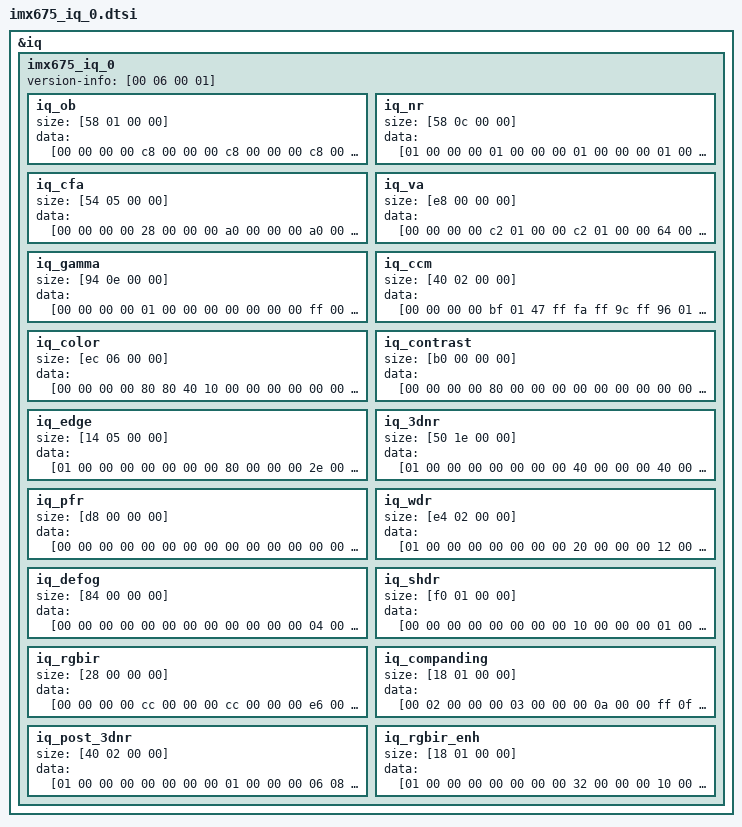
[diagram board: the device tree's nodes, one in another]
/*
 * Novatek Ltd. NA51055 BSP part of dts
 *
 * Cortex-A9
 *
 */

&iq {
	imx675_iq_0 {
		version-info = [00 06 00 01];
		iq_ob {
			size = [58 01 00 00];
			data = [00 00 00 00 c8 00 00 00 c8 00 00 00 c8 00 00 00 c8 00 00 00 c8 00 00 00 c8 00 00 00 c8 00 00 00 c8 00 00 00 c8 00 00 00 c8 00 00 00 c8 00 00 00 c8 00 00 00 c8 00 00 00 c8 00 00 00 c8 00 00 00 c8 00 00 00 c8 00 00 00 c8 00 00 00 c8 00 00 00 c8 00 00 00 c8 00 00 00 c8 00 00 00 c8 00 00 00 c8 00 00 00 c8 00 00 00 c8 00 00 00 c8 00 00 00 c8 00 00 00 c8 00 00 00 c8 00 00 00 c8 00 00 00 c8 00 00 00 c8 00 00 00 c8 00 00 00 c8 00 00 00 c8 00 00 00 c8 00 00 00 c8 00 00 00 c8 00 00 00 c8 00 00 00 c8 00 00 00 c8 00 00 00 c8 00 00 00 c8 00 00 00 c8 00 00 00 c8 00 00 00 c8 00 00 00 c8 00 00 00 c8 00 00 00 c8 00 00 00 c8 00 00 00 c8 00 00 00 c8 00 00 00 c8 00 00 00 c8 00 00 00 c8 00 00 00 c8 00 00 00 c8 00 00 00 c8 00 00 00 c8 00 00 00 c8 00 00 00 c8 00 00 00 c8 00 00 00 c8 00 00 00 c8 00 00 00 c8 00 00 00 c8 00 00 00 c8 00 00 00 c8 00 00 00 c8 00 00 00 c8 00 00 00 c8 00 00 00 c8 00 00 00 c8 00 00 00 c8 00 00 00 c8 00 00 00 c8 00 00 00 c8 00 00 00 c8 00 00 00 c8 00 00 00 c8 00 00 00 c8 00 00 00 c8 00 00 00 c8 00 00 00 c8 00 00 00];
		};
		iq_nr {
			size = [58 0c 00 00];
			data = [01 00 00 00 01 00 00 00 01 00 00 00 01 00 00 00 01 00 00 00 00 00 00 00 00 00 00 00 00 01 00 00 00 00 00 00 ff 0f 00 00 ff 0f 00 00 ff 0f 00 00 ff 0f 00 00 ff 0f 00 00 ff 0f 00 00 ff 0f 00 00 ff 0f 00 00 ff 0f 00 00 ff 0f 00 00 00 01 80 00 00 00 00 00 00 00 00 00 00 00 00 00 00 00 00 00 00 00 00 00 00 00 00 00 00 00 00 00 00 00 00 00 00 00 00 00 00 00 00 00 00 00 00 00 00 00 00 00 00 00 00 00 00 00 00 00 00 00 00 00 00 00 00 00 00 00 00 00 00 00 00 00 00 00 00 00 00 00 00 00 00 00 00 00 00 00 00 00 00 00 00 00 00 00 00 00 00 00 00 00 80 00 00 00 00 00 00 00 00 00 00 00 00 00 00 00 00 00 00 00 00 00 00 00 00 00 00 00 02 00 00 00 02 00 00 00 00 00 00 00 c6 02 00 00 0c 04 00 00 af 06 00 00 3d 09 00 00 41 0f 00 00 c6 02 00 00 0c 04 00 00 af 06 00 00 3d 09 00 00 41 0f 00 00 00 00 80 00 00 00 00 00 01 00 00 00 02 00 00 00 02 00 00 00 02 00 00 00 03 00 00 00 00 00 00 00 02 00 00 00 02 00 00 00 03 00 00 00 03 00 00 00 03 00 00 00 03 00 00 00 04 00 00 00 04 00 00 00 04 00 00 00 04 00 00 00 04 00 00 00 05 00 00 00 05 00 00 00 05 00 00 00 05 00 00 00 05 00 00 00 00 00 00 00 02 00 00 00 80 00 00 00 08 00 00 00 08 00 00 00 08 00 00 00 08 00 00 00 00 00 00 00 01 00 00 00 00 00 00 00 00 00 00 00 00 00 00 00 c6 02 00 00 0c 04 00 00 af 06 00 00 3d 09 00 00 41 0f 00 00 c6 02 00 00 0c 04 00 00 af 06 00 00 3d 09 00 00 41 0f 00 00 02 00 80 00 00 00 00 00 01 00 00 00 02 00 00 00 02 00 00 00 03 00 00 00 03 00 00 00 02 00 00 00 03 00 00 00 05 00 00 00 07 00 00 00 08 00 00 00 08 00 00 00 08 00 00 00 09 00 00 00 0a 00 00 00 0a 00 00 00 0b 00 00 00 0b 00 00 00 0c 00 00 00 0c 00 00 00 0d 00 00 00 0d 00 00 00 0e 00 00 00 00 00 00 00 03 00 00 00 80 00 00 00 08 00 00 00 08 00 00 00 08 00 00 00 08 00 00 00 00 00 00 00 04 00 00 00 00 00 00 00 00 00 00 00 00 00 00 00 20 00 00 00 00 02 00 00 c0 03 00 00 a0 05 00 00 00 0a 00 00 c6 02 00 00 0c 04 00 00 af 06 00 00 3d 09 00 00 41 0f 00 00 02 00 80 00 01 00 00 00 02 00 00 00 02 00 00 00 03 00 00 00 04 00 00 00 05 00 00 00 03 00 00 00 05 00 00 00 08 00 00 00 09 00 00 00 0a 00 00 00 0a 00 00 00 0a 00 00 00 0d 00 00 00 0e 00 00 00 0f 00 00 00 10 00 00 00 0f 00 00 00 0f 00 00 00 10 00 00 00 10 00 00 00 11 00 00 00 12 00 00 00 00 00 00 00 04 00 00 00 80 00 00 00 08 00 00 00 08 00 00 00 08 00 00 00 08 00 00 00 00 00 00 00 04 00 00 00 01 00 00 00 01 00 00 00 00 00 00 00 20 00 00 00 a0 00 00 00 80 01 00 00 00 02 00 00 00 03 00 00 c6 02 00 00 0c 04 00 00 af 06 00 00 3d 09 00 00 41 0f 00 00 09 00 80 00 03 00 00 00 04 00 00 00 04 00 00 00 05 00 00 00 05 00 00 00 06 00 00 00 04 00 00 00 06 00 00 00 09 00 00 00 0b 00 00 00 0b 00 00 00 0c 00 00 00 0e 00 00 00 0f 00 00 00 10 00 00 00 12 00 00 00 12 00 00 00 13 00 00 00 14 00 00 00 14 00 00 00 14 00 00 00 14 00 00 00 14 00 00 00 00 00 00 00 05 00 00 00 80 00 00 00 08 00 00 00 08 00 00 00 08 00 00 00 08 00 00 00 00 00 00 00 06 00 00 00 01 00 00 00 01 00 00 00 00 00 00 00 20 00 00 00 a0 00 00 00 80 01 00 00 00 02 00 00 00 03 00 00 c6 02 00 00 0c 04 00 00 af 06 00 00 3d 09 00 00 41 0f 00 00 09 00 80 00 04 00 00 00 04 00 00 00 05 00 00 00 06 00 00 00 07 00 00 00 07 00 00 00 06 00 00 00 0a 00 00 00 0e 00 00 00 10 00 00 00 11 00 00 00 13 00 00 00 15 00 00 00 17 00 00 00 18 00 00 00 1a 00 00 00 1b 00 00 00 1b 00 00 00 1b 00 00 00 1b 00 00 00 1b 00 00 00 1b 00 00 00 1b 00 00 00 00 00 00 00 05 00 00 00 80 00 00 00 08 00 00 00 08 00 00 00 08 00 00 00 08 00 00 00 01 00 00 00 08 00 00 00 02 00 00 00 02 00 00 00 00 00 00 00 20 00 00 00 64 00 00 00 c8 00 00 00 2c 01 00 00 00 02 00 00 c6 02 00 00 0c 04 00 00 af 06 00 00 3d 09 00 00 41 0f 00 00 09 00 80 00 06 00 00 00 07 00 00 00 08 00 00 00 09 00 00 00 09 00 00 00 0b 00 00 00 0c 00 00 00 0f 00 00 00 14 00 00 00 16 00 00 00 17 00 00 00 19 00 00 00 1b 00 00 00 1d 00 00 00 1f 00 00 00 21 00 00 00 22 00 00 00 24 00 00 00 25 00 00 00 27 00 00 00 28 00 00 00 29 00 00 00 2b 00 00 00 00 00 00 00 06 00 00 00 80 00 00 00 0a 00 00 00 0a 00 00 00 10 00 00 00 10 00 00 00 01 00 00 00 0a 00 00 00 02 00 00 00 02 00 00 00 00 00 00 00 20 00 00 00 90 00 00 00 c0 00 00 00 80 01 00 00 80 02 00 00 c6 02 00 00 0c 04 00 00 af 06 00 00 3d 09 00 00 41 0f 00 00 09 00 80 00 00 00 00 00 06 00 00 00 09 00 00 00 0b 00 00 00 0c 00 00 00 12 00 00 00 00 00 00 00 0c 00 00 00 0f 00 00 00 1c 00 00 00 1f 00 00 00 21 00 00 00 24 00 00 00 26 00 00 00 28 00 00 00 2a 00 00 00 2c 00 00 00 2e 00 00 00 30 00 00 00 31 00 00 00 33 00 00 00 34 00 00 00 36 00 00 00 02 00 00 00 08 00 00 00 40 00 00 00 0a 00 00 00 0a 00 00 00 10 00 00 00 10 00 00 00 00 00 00 00 0a 00 00 00 02 00 00 00 02 00 00 00 00 00 00 00 20 00 00 00 80 00 00 00 a0 00 00 00 00 01 00 00 00 02 00 00 c6 02 00 00 0c 04 00 00 af 06 00 00 3d 09 00 00 41 0f 00 00 09 00 80 00 00 00 00 00 06 00 00 00 08 00 00 00 0a 00 00 00 0c 00 00 00 11 00 00 00 00 00 00 00 10 00 00 00 17 00 00 00 1c 00 00 00 20 00 00 00 24 00 00 00 28 00 00 00 2b 00 00 00 2e 00 00 00 31 00 00 00 33 00 00 00 36 00 00 00 38 00 00 00 3b 00 00 00 3d 00 00 00 3f 00 00 00 41 00 00 00 00 00 00 00 20 00 00 00 40 00 00 00 10 00 00 00 10 00 00 00 10 00 00 00 10 00 00 00 00 00 00 00 10 00 00 00 02 00 00 00 02 00 00 00 00 00 00 00 c6 02 00 00 0c 04 00 00 af 06 00 00 3d 09 00 00 41 0f 00 00 c6 02 00 00 0c 04 00 00 af 06 00 00 3d 09 00 00 41 0f 00 00 09 00 80 00 00 00 00 00 0b 00 00 00 10 00 00 00 13 00 00 00 16 00 00 00 20 00 00 00 00 00 00 00 0f 00 00 00 1e 00 00 00 25 00 00 00 2b 00 00 00 30 00 00 00 34 00 00 00 39 00 00 00 3d 00 00 00 40 00 00 00 44 00 00 00 47 00 00 00 4a 00 00 00 4d 00 00 00 50 00 00 00 53 00 00 00 56 00 00 00 00 00 00 00 20 00 00 00 40 00 00 00 10 00 00 00 10 00 00 00 10 00 00 00 10 00 00 00 00 00 00 00 12 00 00 00 02 00 00 00 03 00 00 00 00 00 00 00 c6 02 00 00 0c 04 00 00 af 06 00 00 3d 09 00 00 41 0f 00 00 c6 02 00 00 0c 04 00 00 af 06 00 00 3d 09 00 00 41 0f 00 00 09 00 80 00 00 00 00 00 11 00 00 00 19 00 00 00 1f 00 00 00 23 00 00 00 32 00 00 00 00 00 00 00 18 00 00 00 2e 00 00 00 3f 00 00 00 49 00 00 00 52 00 00 00 5a 00 00 00 61 00 00 00 68 00 00 00 6e 00 00 00 74 00 00 00 7a 00 00 00 7f 00 00 00 84 00 00 00 89 00 00 00 8e 00 00 00 93 00 00 00 00 00 00 00 20 00 00 00 40 00 00 00 10 00 00 00 10 00 00 00 10 00 00 00 10 00 00 00 00 00 00 00 16 00 00 00 02 00 00 00 03 00 00 00 00 00 00 00 c6 02 00 00 0c 04 00 00 af 06 00 00 3d 09 00 00 41 0f 00 00 c6 02 00 00 0c 04 00 00 af 06 00 00 3d 09 00 00 41 0f 00 00 09 00 80 00 00 00 00 00 21 00 00 00 2f 00 00 00 3a 00 00 00 43 00 00 00 5e 00 00 00 00 00 00 00 38 00 00 00 4f 00 00 00 60 00 00 00 70 00 00 00 7d 00 00 00 89 00 00 00 94 00 00 00 9e 00 00 00 a8 00 00 00 b1 00 00 00 b9 00 00 00 c1 00 00 00 c9 00 00 00 d1 00 00 00 d8 00 00 00 e0 00 00 00 00 00 00 00 20 00 00 00 40 00 00 00 10 00 00 00 10 00 00 00 10 00 00 00 10 00 00 00 00 00 00 00 16 00 00 00 02 00 00 00 03 00 00 00 00 00 00 00 c6 02 00 00 0c 04 00 00 af 06 00 00 3d 09 00 00 41 0f 00 00 c6 02 00 00 0c 04 00 00 af 06 00 00 3d 09 00 00 41 0f 00 00 09 00 80 00 00 00 00 00 10 00 00 00 16 00 00 00 1c 00 00 00 20 00 00 00 2d 00 00 00 00 00 00 00 12 00 00 00 18 00 00 00 20 00 00 00 25 00 00 00 2a 00 00 00 2e 00 00 00 31 00 00 00 35 00 00 00 38 00 00 00 3b 00 00 00 3e 00 00 00 41 00 00 00 43 00 00 00 46 00 00 00 48 00 00 00 4b 00 00 00 00 00 00 00 20 00 00 00 20 00 00 00 10 00 00 00 10 00 00 00 10 00 00 00 10 00 00 00 00 00 00 00 18 00 00 00 02 00 00 00 03 00 00 00 00 00 00 00 14 02 00 00 03 03 00 00 f8 04 00 00 34 07 00 00 e3 0b 00 00 14 02 00 00 03 03 00 00 f8 04 00 00 34 07 00 00 e3 0b 00 00 09 00 80 00 00 00 00 00 11 00 00 00 18 00 00 00 1e 00 00 00 23 00 00 00 31 00 00 00 00 00 00 00 30 00 00 00 43 00 00 00 53 00 00 00 60 00 00 00 6b 00 00 00 75 00 00 00 7e 00 00 00 87 00 00 00 90 00 00 00 97 00 00 00 9f 00 00 00 a6 00 00 00 ad 00 00 00 b3 00 00 00 b9 00 00 00 c0 00 00 00 00 00 00 00 20 00 00 00 20 00 00 00 18 00 00 00 18 00 00 00 18 00 00 00 18 00 00 00 00 00 00 00 12 00 00 00 02 00 00 00 02 00 00 00 00 00 00 00 9a 01 00 00 53 02 00 00 d6 03 00 00 90 05 00 00 2e 09 00 00 9a 01 00 00 53 02 00 00 d6 03 00 00 90 05 00 00 2e 09 00 00 09 00 80 00 00 00 00 00 11 00 00 00 18 00 00 00 1e 00 00 00 23 00 00 00 31 00 00 00 00 00 00 00 30 00 00 00 43 00 00 00 53 00 00 00 60 00 00 00 6b 00 00 00 75 00 00 00 7e 00 00 00 87 00 00 00 90 00 00 00 97 00 00 00 9f 00 00 00 a6 00 00 00 ad 00 00 00 b3 00 00 00 b9 00 00 00 c0 00 00 00 00 00 00 00 20 00 00 00 20 00 00 00 18 00 00 00 18 00 00 00 18 00 00 00 18 00 00 00 00 00 00 00 12 00 00 00 02 00 00 00 02 00 00 00 00 00 00 00 9a 01 00 00 53 02 00 00 d6 03 00 00 90 05 00 00 2e 09 00 00 9a 01 00 00 53 02 00 00 d6 03 00 00 90 05 00 00 2e 09 00 00 09 00 80 00 00 00 00 00 11 00 00 00 18 00 00 00 1e 00 00 00 23 00 00 00 31 00 00 00 00 00 00 00 30 00 00 00 43 00 00 00 53 00 00 00 60 00 00 00 6b 00 00 00 75 00 00 00 7e 00 00 00 87 00 00 00 90 00 00 00 97 00 00 00 9f 00 00 00 a6 00 00 00 ad 00 00 00 b3 00 00 00 b9 00 00 00 c0 00 00 00 00 00 00 00 20 00 00 00 20 00 00 00 18 00 00 00 18 00 00 00 18 00 00 00 18 00 00 00 00 00 00 00 12 00 00 00 02 00 00 00 02 00 00 00 00 00 00 00 9a 01 00 00 53 02 00 00 d6 03 00 00 90 05 00 00 2e 09 00 00 9a 01 00 00 53 02 00 00 d6 03 00 00 90 05 00 00 2e 09 00 00 09 00 80 00 00 00 00 00 11 00 00 00 18 00 00 00 1e 00 00 00 23 00 00 00 31 00 00 00 00 00 00 00 30 00 00 00 43 00 00 00 53 00 00 00 60 00 00 00 6b 00 00 00 75 00 00 00 7e 00 00 00 87 00 00 00 90 00 00 00 97 00 00 00 9f 00 00 00 a6 00 00 00 ad 00 00 00 b3 00 00 00 b9 00 00 00 c0 00 00 00 00 00 00 00 20 00 00 00 20 00 00 00 18 00 00 00 18 00 00 00 18 00 00 00 18 00 00 00 00 00 00 00 12 00 00 00 02 00 00 00 02 00 00 00];
		};
		iq_cfa {
			size = [54 05 00 00];
			data = [00 00 00 00 28 00 00 00 a0 00 00 00 a0 00 00 00 40 00 00 00 0f 00 00 00 0f 00 00 00 07 00 00 00 04 00 00 00 03 00 00 00 02 00 00 00 02 00 00 00 01 00 00 00 01 00 00 00 01 00 00 00 01 00 00 00 00 00 00 00 00 00 00 00 00 00 00 00 00 00 00 00 00 00 00 00 28 00 00 00 a0 00 00 00 a0 00 00 00 40 00 00 00 0f 00 00 00 0f 00 00 00 07 00 00 00 04 00 00 00 03 00 00 00 02 00 00 00 02 00 00 00 01 00 00 00 01 00 00 00 01 00 00 00 01 00 00 00 00 00 00 00 00 00 00 00 00 00 00 00 00 00 00 00 00 00 00 00 28 00 00 00 a0 00 00 00 a0 00 00 00 40 00 00 00 0f 00 00 00 0f 00 00 00 07 00 00 00 04 00 00 00 03 00 00 00 02 00 00 00 02 00 00 00 01 00 00 00 01 00 00 00 01 00 00 00 01 00 00 00 00 00 00 00 00 00 00 00 00 00 00 00 00 00 00 00 00 00 00 00 28 00 00 00 a0 00 00 00 a0 00 00 00 40 00 00 00 0f 00 00 00 0f 00 00 00 07 00 00 00 04 00 00 00 03 00 00 00 02 00 00 00 02 00 00 00 01 00 00 00 01 00 00 00 01 00 00 00 01 00 00 00 00 00 00 00 00 00 00 00 00 00 00 00 00 00 00 00 00 00 00 00 28 00 00 00 a0 00 00 00 a0 00 00 00 40 00 00 00 0f 00 00 00 0f 00 00 00 07 00 00 00 04 00 00 00 03 00 00 00 02 00 00 00 02 00 00 00 01 00 00 00 01 00 00 00 01 00 00 00 01 00 00 00 00 00 00 00 00 00 00 00 00 00 00 00 00 00 00 00 00 00 00 00 28 00 00 00 a0 00 00 00 a0 00 00 00 40 00 00 00 0f 00 00 00 0f 00 00 00 07 00 00 00 04 00 00 00 03 00 00 00 02 00 00 00 02 00 00 00 01 00 00 00 01 00 00 00 01 00 00 00 01 00 00 00 00 00 00 00 00 00 00 00 00 00 00 00 00 00 00 00 00 00 00 00 28 00 00 00 a0 00 00 00 a0 00 00 00 40 00 00 00 0f 00 00 00 0f 00 00 00 07 00 00 00 04 00 00 00 03 00 00 00 02 00 00 00 02 00 00 00 01 00 00 00 01 00 00 00 01 00 00 00 01 00 00 00 00 00 00 00 00 00 00 00 00 00 00 00 00 00 00 00 00 00 00 00 28 00 00 00 a0 00 00 00 a0 00 00 00 40 00 00 00 0f 00 00 00 0f 00 00 00 07 00 00 00 04 00 00 00 03 00 00 00 02 00 00 00 02 00 00 00 01 00 00 00 01 00 00 00 01 00 00 00 01 00 00 00 00 00 00 00 00 00 00 00 00 00 00 00 00 00 00 00 00 00 00 00 28 00 00 00 a0 00 00 00 a0 00 00 00 40 00 00 00 0f 00 00 00 0f 00 00 00 07 00 00 00 04 00 00 00 03 00 00 00 02 00 00 00 02 00 00 00 01 00 00 00 01 00 00 00 01 00 00 00 01 00 00 00 00 00 00 00 00 00 00 00 00 00 00 00 00 00 00 00 00 00 00 00 28 00 00 00 a0 00 00 00 a0 00 00 00 40 00 00 00 0f 00 00 00 0f 00 00 00 07 00 00 00 04 00 00 00 03 00 00 00 02 00 00 00 02 00 00 00 01 00 00 00 01 00 00 00 01 00 00 00 01 00 00 00 00 00 00 00 00 00 00 00 00 00 00 00 00 00 00 00 00 00 00 00 28 00 00 00 a0 00 00 00 a0 00 00 00 40 00 00 00 0f 00 00 00 0f 00 00 00 07 00 00 00 04 00 00 00 03 00 00 00 02 00 00 00 02 00 00 00 01 00 00 00 01 00 00 00 01 00 00 00 01 00 00 00 00 00 00 00 00 00 00 00 00 00 00 00 00 00 00 00 00 00 00 00 28 00 00 00 a0 00 00 00 a0 00 00 00 40 00 00 00 0f 00 00 00 0f 00 00 00 07 00 00 00 04 00 00 00 03 00 00 00 02 00 00 00 02 00 00 00 01 00 00 00 01 00 00 00 01 00 00 00 01 00 00 00 00 00 00 00 00 00 00 00 00 00 00 00 00 00 00 00 00 00 00 00 28 00 00 00 a0 00 00 00 a0 00 00 00 40 00 00 00 0f 00 00 00 0f 00 00 00 07 00 00 00 04 00 00 00 03 00 00 00 02 00 00 00 02 00 00 00 01 00 00 00 01 00 00 00 01 00 00 00 01 00 00 00 00 00 00 00 00 00 00 00 00 00 00 00 00 00 00 00 00 00 00 00 28 00 00 00 a0 00 00 00 a0 00 00 00 40 00 00 00 0f 00 00 00 0f 00 00 00 07 00 00 00 04 00 00 00 03 00 00 00 02 00 00 00 02 00 00 00 01 00 00 00 01 00 00 00 01 00 00 00 01 00 00 00 00 00 00 00 00 00 00 00 00 00 00 00 00 00 00 00 00 00 00 00 28 00 00 00 a0 00 00 00 a0 00 00 00 40 00 00 00 0f 00 00 00 0f 00 00 00 07 00 00 00 04 00 00 00 03 00 00 00 02 00 00 00 02 00 00 00 01 00 00 00 01 00 00 00 01 00 00 00 01 00 00 00 00 00 00 00 00 00 00 00 00 00 00 00 00 00 00 00 00 00 00 00 28 00 00 00 a0 00 00 00 a0 00 00 00 40 00 00 00 0f 00 00 00 0f 00 00 00 07 00 00 00 04 00 00 00 03 00 00 00 02 00 00 00 02 00 00 00 01 00 00 00 01 00 00 00 01 00 00 00 01 00 00 00 00 00 00 00 00 00 00 00 00 00 00 00 00 00 00 00 00 00 00 00 28 00 00 00 a0 00 00 00 a0 00 00 00 40 00 00 00 0f 00 00 00 0f 00 00 00 07 00 00 00 04 00 00 00 03 00 00 00 02 00 00 00 02 00 00 00 01 00 00 00 01 00 00 00 01 00 00 00 01 00 00 00 00 00 00 00 00 00 00 00 00 00 00 00 00 00 00 00 00 00 00 00];
		};
		iq_va {
			size = [e8 00 00 00];
			data = [00 00 00 00 c2 01 00 00 c2 01 00 00 64 00 00 00 64 00 00 00 c8 00 00 00 c8 00 00 00 64 00 00 00 64 00 00 00 bc 02 00 00 c8 00 00 00 64 00 00 00 64 00 00 00 c8 00 00 00 bc 02 00 00 64 00 00 00 64 00 00 00 bc 02 00 00 bc 02 00 00 64 00 00 00 64 00 00 00 02 ff 00 00 03 02 00 ff 00 03 06 00 08 00 06 00 08 00 06 00 08 00 06 00 08 00 06 00 08 00 06 00 08 00 06 00 08 00 06 00 08 00 06 00 08 00 06 00 08 00 06 00 08 00 06 00 08 00 06 00 08 00 06 00 08 00 06 00 08 00 06 00 08 00 06 00 08 00 06 00 08 00 06 00 08 00 06 00 08 00 06 00 08 00 06 00 08 00 06 00 08 00 06 00 08 00 06 00 08 00 06 00 08 00 06 00 08 00 06 00 08 00 06 00 08 00 06 00 08 00 06 00 08 00 06 00 08 00 06 00 08 00 06 00 08 00 00 00];
		};
		iq_gamma {
			size = [94 0e 00 00];
			data = [00 00 00 00 01 00 00 00 00 00 00 00 ff 00 00 00 ff 00 00 00 ff 00 00 00 ff 00 00 00 ff 00 00 00 ff 00 00 00 ff 00 00 00 ff 00 00 00 ff 00 00 00 ff 00 00 00 ff 00 00 00 ff 00 00 00 ff 00 00 00 ff 00 00 00 ff 00 00 00 ff 00 00 00 ff 00 00 00 00 00 00 00 08 00 00 00 10 00 00 00 18 00 00 00 1c 00 00 00 20 00 00 00 24 00 00 00 26 00 00 00 28 00 00 00 29 00 00 00 2a 00 00 00 2b 00 00 00 2c 00 00 00 2d 00 00 00 2e 00 00 00 2f 00 00 00 30 00 00 00 31 00 00 00 32 00 00 00 33 00 00 00 34 00 00 00 35 00 00 00 36 00 00 00 37 00 00 00 38 00 00 00 39 00 00 00 3a 00 00 00 3b 00 00 00 3c 00 00 00 3d 00 00 00 3e 00 00 00 3f 00 00 00 03 00 00 00 03 00 00 00 03 00 00 00 02 00 00 00 02 00 00 00 02 00 00 00 01 00 00 00 01 00 00 00 00 00 00 00 00 00 00 00 00 00 00 00 00 00 00 00 00 00 00 00 00 00 00 00 00 00 00 00 00 00 00 00 00 00 00 00 00 00 00 00 00 00 00 00 00 00 00 00 00 00 00 00 00 00 00 00 00 00 00 00 00 00 00 00 00 00 00 00 00 00 00 00 00 00 00 00 00 00 00 00 00 00 00 00 00 00 00 00 00 00 00 00 00 00 00 00 00 00 00 00 1a 00 00 00 32 00 00 00 46 00 00 00 5a 00 00 00 6e 00 00 00 82 00 00 00 92 00 00 00 a4 00 00 00 b6 00 00 00 c9 00 00 00 dc 00 00 00 f0 00 00 00 03 01 00 00 17 01 00 00 2c 01 00 00 40 01 00 00 52 01 00 00 65 01 00 00 77 01 00 00 89 01 00 00 9a 01 00 00 ab 01 00 00 bb 01 00 00 cc 01 00 00 ef 01 00 00 12 02 00 00 35 02 00 00 59 02 00 00 76 02 00 00 94 02 00 00 b1 02 00 00 ce 02 00 00 ea 02 00 00 06 03 00 00 21 03 00 00 3d 03 00 00 75 03 00 00 af 03 00 00 e9 03 00 00 24 04 00 00 9b 04 00 00 14 05 00 00 90 05 00 00 09 06 00 00 86 06 00 00 00 07 00 00 80 07 00 00 00 08 00 00 80 08 00 00 00 09 00 00 80 09 00 00 00 0a 00 00 80 0a 00 00 00 0b 00 00 80 0b 00 00 00 0c 00 00 80 0c 00 00 00 0d 00 00 80 0d 00 00 00 0e 00 00 80 0e 00 00 00 0f 00 00 80 0f 00 00 ff 0f 00 00 00 00 00 00 08 00 00 00 10 00 00 00 18 00 00 00 1c 00 00 00 20 00 00 00 24 00 00 00 26 00 00 00 28 00 00 00 29 00 00 00 2a 00 00 00 2b 00 00 00 2c 00 00 00 2d 00 00 00 2e 00 00 00 2f 00 00 00 30 00 00 00 31 00 00 00 32 00 00 00 33 00 00 00 34 00 00 00 35 00 00 00 36 00 00 00 37 00 00 00 38 00 00 00 39 00 00 00 3a 00 00 00 3b 00 00 00 3c 00 00 00 3d 00 00 00 3e 00 00 00 3f 00 00 00 03 00 00 00 03 00 00 00 03 00 00 00 02 00 00 00 02 00 00 00 02 00 00 00 01 00 00 00 01 00 00 00 00 00 00 00 00 00 00 00 00 00 00 00 00 00 00 00 00 00 00 00 00 00 00 00 00 00 00 00 00 00 00 00 00 00 00 00 00 00 00 00 00 00 00 00 00 00 00 00 00 00 00 00 00 00 00 00 00 00 00 00 00 00 00 00 00 00 00 00 00 00 00 00 00 00 00 00 00 00 00 00 00 00 00 00 00 00 00 00 00 00 00 00 00 00 00 00 05 00 00 00 00 00 00 00 00 00 00 00 10 00 00 00 20 00 00 00 30 00 00 00 40 00 00 00 50 00 00 00 60 00 00 00 70 00 00 00 80 00 00 00 90 00 00 00 a0 00 00 00 b0 00 00 00 c0 00 00 00 d0 00 00 00 e0 00 00 00 f0 00 00 00 00 01 00 00 10 01 00 00 20 01 00 00 30 01 00 00 40 01 00 00 50 01 00 00 60 01 00 00 70 01 00 00 80 01 00 00 a0 01 00 00 c0 01 00 00 e0 01 00 00 00 02 00 00 20 02 00 00 40 02 00 00 60 02 00 00 80 02 00 00 a0 02 00 00 c0 02 00 00 e0 02 00 00 00 03 00 00 40 03 00 00 80 03 00 00 c0 03 00 00 00 04 00 00 80 04 00 00 00 05 00 00 80 05 00 00 00 06 00 00 80 06 00 00 00 07 00 00 80 07 00 00 00 08 00 00 80 08 00 00 00 09 00 00 80 09 00 00 00 0a 00 00 80 0a 00 00 00 0b 00 00 80 0b 00 00 00 0c 00 00 80 0c 00 00 00 0d 00 00 80 0d 00 00 00 0e 00 00 80 0e 00 00 00 0f 00 00 80 0f 00 00 ff 0f 00 00 19 00 00 00 00 00 00 00 10 00 00 00 20 00 00 00 30 00 00 00 40 00 00 00 50 00 00 00 60 00 00 00 70 00 00 00 80 00 00 00 90 00 00 00 a0 00 00 00 b0 00 00 00 c0 00 00 00 d0 00 00 00 e0 00 00 00 f0 00 00 00 00 01 00 00 10 01 00 00 20 01 00 00 30 01 00 00 40 01 00 00 50 01 00 00 60 01 00 00 70 01 00 00 80 01 00 00 a0 01 00 00 c0 01 00 00 e0 01 00 00 00 02 00 00 20 02 00 00 40 02 00 00 60 02 00 00 80 02 00 00 a0 02 00 00 c0 02 00 00 e0 02 00 00 00 03 00 00 40 03 00 00 80 03 00 00 c0 03 00 00 00 04 00 00 80 04 00 00 00 05 00 00 80 05 00 00 00 06 00 00 80 06 00 00 00 07 00 00 80 07 00 00 00 08 00 00 80 08 00 00 00 09 00 00 80 09 00 00 00 0a 00 00 80 0a 00 00 00 0b 00 00 80 0b 00 00 00 0c 00 00 80 0c 00 00 00 0d 00 00 80 0d 00 00 00 0e 00 00 80 0e 00 00 00 0f 00 00 80 0f 00 00 ff 0f 00 00 32 00 00 00 00 00 00 00 10 00 00 00 20 00 00 00 30 00 00 00 40 00 00 00 50 00 00 00 60 00 00 00 70 00 00 00 80 00 00 00 90 00 00 00 a0 00 00 00 b0 00 00 00 c0 00 00 00 d0 00 00 00 e0 00 00 00 f0 00 00 00 00 01 00 00 10 01 00 00 20 01 00 00 30 01 00 00 40 01 00 00 50 01 00 00 60 01 00 00 70 01 00 00 80 01 00 00 a0 01 00 00 c0 01 00 00 e0 01 00 00 00 02 00 00 20 02 00 00 40 02 00 00 60 02 00 00 80 02 00 00 a0 02 00 00 c0 02 00 00 e0 02 00 00 00 03 00 00 40 03 00 00 80 03 00 00 c0 03 00 00 00 04 00 00 80 04 00 00 00 05 00 00 80 05 00 00 00 06 00 00 80 06 00 00 00 07 00 00 80 07 00 00 00 08 00 00 80 08 00 00 00 09 00 00 80 09 00 00 00 0a 00 00 80 0a 00 00 00 0b 00 00 80 0b 00 00 00 0c 00 00 80 0c 00 00 00 0d 00 00 80 0d 00 00 00 0e 00 00 80 0e 00 00 00 0f 00 00 80 0f 00 00 ff 0f 00 00 4b 00 00 00 00 00 00 00 10 00 00 00 20 00 00 00 30 00 00 00 40 00 00 00 50 00 00 00 60 00 00 00 70 00 00 00 80 00 00 00 90 00 00 00 a0 00 00 00 b0 00 00 00 c0 00 00 00 d0 00 00 00 e0 00 00 00 f0 00 00 00 00 01 00 00 10 01 00 00 20 01 00 00 30 01 00 00 40 01 00 00 50 01 00 00 60 01 00 00 70 01 00 00 80 01 00 00 a0 01 00 00 c0 01 00 00 e0 01 00 00 00 02 00 00 20 02 00 00 40 02 00 00 60 02 00 00 80 02 00 00 a0 02 00 00 c0 02 00 00 e0 02 00 00 00 03 00 00 40 03 00 00 80 03 00 00 c0 03 00 00 00 04 00 00 80 04 00 00 00 05 00 00 80 05 00 00 00 06 00 00 80 06 00 00 00 07 00 00 80 07 00 00 00 08 00 00 80 08 00 00 00 09 00 00 80 09 00 00 00 0a 00 00 80 0a 00 00 00 0b 00 00 80 0b 00 00 00 0c 00 00 80 0c 00 00 00 0d 00 00 80 0d 00 00 00 0e 00 00 80 0e 00 00 00 0f 00 00 80 0f 00 00 ff 0f 00 00 64 00 00 00 00 00 00 00 10 00 00 00 20 00 00 00 30 00 00 00 40 00 00 00 50 00 00 00 60 00 00 00 70 00 00 00 80 00 00 00 90 00 00 00 a0 00 00 00 b0 00 00 00 c0 00 00 00 d0 00 00 00 e0 00 00 00 f0 00 00 00 00 01 00 00 10 01 00 00 20 01 00 00 30 01 00 00 40 01 00 00 50 01 00 00 60 01 00 00 70 01 00 00 80 01 00 00 a0 01 00 00 c0 01 00 00 e0 01 00 00 00 02 00 00 20 02 00 00 40 02 00 00 60 02 00 00 80 02 00 00 a0 02 00 00 c0 02 00 00 e0 02 00 00 00 03 00 00 40 03 00 00 80 03 00 00 c0 03 00 00 00 04 00 00 80 04 00 00 00 05 00 00 80 05 00 00 00 06 00 00 80 06 00 00 00 07 00 00 80 07 00 00 00 08 00 00 80 08 00 00 00 09 00 00 80 09 00 00 00 0a 00 00 80 0a 00 00 00 0b 00 00 80 0b 00 00 00 0c 00 00 80 0c 00 00 00 0d 00 00 80 0d 00 00 00 0e 00 00 80 0e 00 00 00 0f 00 00 80 0f 00 00 ff 0f 00 00 00 00 00 00 25 00 00 00 49 00 00 00 6b 00 00 00 8b 00 00 00 a9 00 00 00 c6 00 00 00 e1 00 00 00 f1 00 00 00 01 01 00 00 11 01 00 00 21 01 00 00 30 01 00 00 3e 01 00 00 4d 01 00 00 5b 01 00 00 68 01 00 00 75 01 00 00 82 01 00 00 8f 01 00 00 9b 01 00 00 a6 01 00 00 b1 01 00 00 bc 01 00 00 c7 01 00 00 d1 01 00 00 db 01 00 00 e4 01 00 00 ed 01 00 00 f6 01 00 00 fe 01 00 00 06 02 00 00 0d 02 00 00 14 02 00 00 1b 02 00 00 22 02 00 00 29 02 00 00 30 02 00 00 36 02 00 00 3d 02 00 00 44 02 00 00 4b 02 00 00 52 02 00 00 59 02 00 00 5f 02 00 00 66 02 00 00 6d 02 00 00 73 02 00 00 7a 02 00 00 80 02 00 00 87 02 00 00 8d 02 00 00 93 02 00 00 9a 02 00 00 a0 02 00 00 a6 02 00 00 ac 02 00 00 b3 02 00 00 b9 02 00 00 bf 02 00 00 c5 02 00 00 cb 02 00 00 d1 02 00 00 d7 02 00 00 dd 02 00 00 e3 02 00 00 e8 02 00 00 ee 02 00 00 f4 02 00 00 fa 02 00 00 ff 02 00 00 04 03 00 00 09 03 00 00 0e 03 00 00 13 03 00 00 18 03 00 00 1d 03 00 00 21 03 00 00 26 03 00 00 2b 03 00 00 30 03 00 00 35 03 00 00 3a 03 00 00 3e 03 00 00 43 03 00 00 48 03 00 00 4d 03 00 00 51 03 00 00 56 03 00 00 5b 03 00 00 5f 03 00 00 64 03 00 00 68 03 00 00 6d 03 00 00 72 03 00 00 76 03 00 00 7b 03 00 00 7f 03 00 00 84 03 00 00 88 03 00 00 8c 03 00 00 91 03 00 00 95 03 00 00 99 03 00 00 9e 03 00 00 a2 03 00 00 a6 03 00 00 ab 03 00 00 af 03 00 00 b3 03 00 00 b7 03 00 00 bb 03 00 00 bf 03 00 00 c4 03 00 00 c8 03 00 00 cc 03 00 00 d0 03 00 00 d4 03 00 00 d8 03 00 00 dc 03 00 00 e0 03 00 00 e4 03 00 00 e8 03 00 00 eb 03 00 00 ef 03 00 00 f3 03 00 00 f7 03 00 00 fb 03 00 00 ff 03 00 00 07 00 00 00 00 00 00 00 43 00 00 00 7b 00 00 00 a7 00 00 00 c1 00 00 00 db 00 00 00 f6 00 00 00 0f 01 00 00 24 01 00 00 37 01 00 00 4a 01 00 00 5a 01 00 00 69 01 00 00 78 01 00 00 85 01 00 00 90 01 00 00 9b 01 00 00 a4 01 00 00 ac 01 00 00 b4 01 00 00 bc 01 00 00 c5 01 00 00 ce 01 00 00 d6 01 00 00 de 01 00 00 e7 01 00 00 ef 01 00 00 f6 01 00 00 fe 01 00 00 06 02 00 00 0d 02 00 00 14 02 00 00 1c 02 00 00 23 02 00 00 2a 02 00 00 31 02 00 00 38 02 00 00 3f 02 00 00 46 02 00 00 4d 02 00 00 54 02 00 00 5a 02 00 00 61 02 00 00 68 02 00 00 6e 02 00 00 75 02 00 00 7b 02 00 00 81 02 00 00 88 02 00 00 8e 02 00 00 94 02 00 00 9a 02 00 00 a0 02 00 00 a6 02 00 00 ac 02 00 00 b2 02 00 00 b8 02 00 00 be 02 00 00 c4 02 00 00 ca 02 00 00 cf 02 00 00 d5 02 00 00 db 02 00 00 e0 02 00 00 e6 02 00 00 eb 02 00 00 f1 02 00 00 f6 02 00 00 fb 02 00 00 01 03 00 00 06 03 00 00 0b 03 00 00 10 03 00 00 15 03 00 00 1a 03 00 00 1f 03 00 00 24 03 00 00 29 03 00 00 2e 03 00 00 33 03 00 00 38 03 00 00 3c 03 00 00 41 03 00 00 46 03 00 00 4a 03 00 00 4f 03 00 00 53 03 00 00 58 03 00 00 5c 03 00 00 60 03 00 00 65 03 00 00 69 03 00 00 6d 03 00 00 71 03 00 00 76 03 00 00 7a 03 00 00 7e 03 00 00 83 03 00 00 87 03 00 00 8b 03 00 00 90 03 00 00 94 03 00 00 98 03 00 00 9d 03 00 00 a1 03 00 00 a5 03 00 00 a9 03 00 00 ad 03 00 00 b1 03 00 00 b5 03 00 00 ba 03 00 00 be 03 00 00 c2 03 00 00 c6 03 00 00 ca 03 00 00 cd 03 00 00 d1 03 00 00 d5 03 00 00 d9 03 00 00 dd 03 00 00 e1 03 00 00 e5 03 00 00 e8 03 00 00 ec 03 00 00 f0 03 00 00 f4 03 00 00 f7 03 00 00 fb 03 00 00 ff 03 00 00 04 00 00 00 00 00 00 00 49 00 00 00 82 00 00 00 9c 00 00 00 c3 00 00 00 f5 00 00 00 16 01 00 00 28 01 00 00 3c 01 00 00 4c 01 00 00 59 01 00 00 66 01 00 00 71 01 00 00 7c 01 00 00 87 01 00 00 91 01 00 00 9c 01 00 00 a6 01 00 00 af 01 00 00 b9 01 00 00 c2 01 00 00 ca 01 00 00 d3 01 00 00 d9 01 00 00 e0 01 00 00 e7 01 00 00 ee 01 00 00 f4 01 00 00 fb 01 00 00 01 02 00 00 07 02 00 00 0e 02 00 00 13 02 00 00 19 02 00 00 1e 02 00 00 24 02 00 00 29 02 00 00 2f 02 00 00 34 02 00 00 3a 02 00 00 3f 02 00 00 45 02 00 00 4a 02 00 00 50 02 00 00 55 02 00 00 5b 02 00 00 60 02 00 00 66 02 00 00 6b 02 00 00 71 02 00 00 76 02 00 00 7c 02 00 00 82 02 00 00 87 02 00 00 8d 02 00 00 92 02 00 00 98 02 00 00 9e 02 00 00 a3 02 00 00 a9 02 00 00 ae 02 00 00 b3 02 00 00 b9 02 00 00 be 02 00 00 c4 02 00 00 c9 02 00 00 ce 02 00 00 d4 02 00 00 d8 02 00 00 dd 02 00 00 e2 02 00 00 e7 02 00 00 eb 02 00 00 f0 02 00 00 f5 02 00 00 fa 02 00 00 ff 02 00 00 04 03 00 00 08 03 00 00 0d 03 00 00 12 03 00 00 17 03 00 00 1c 03 00 00 21 03 00 00 25 03 00 00 2a 03 00 00 2f 03 00 00 34 03 00 00 39 03 00 00 3e 03 00 00 43 03 00 00 47 03 00 00 4c 03 00 00 51 03 00 00 56 03 00 00 5b 03 00 00 60 03 00 00 65 03 00 00 6a 03 00 00 6f 03 00 00 74 03 00 00 78 03 00 00 7d 03 00 00 82 03 00 00 87 03 00 00 8c 03 00 00 91 03 00 00 96 03 00 00 9b 03 00 00 a0 03 00 00 a5 03 00 00 aa 03 00 00 af 03 00 00 b4 03 00 00 b9 03 00 00 be 03 00 00 c3 03 00 00 c8 03 00 00 cd 03 00 00 d1 03 00 00 d6 03 00 00 db 03 00 00 e0 03 00 00 e5 03 00 00 ea 03 00 00 ef 03 00 00 f4 03 00 00 f9 03 00 00 ff 03 00 00];
		};
		iq_ccm {
			size = [40 02 00 00];
			data = [00 00 00 00 bf 01 47 ff fa ff 9c ff 96 01 ce ff 0d 00 e3 fe 0f 02 80 80 80 80 80 80 80 80 80 80 80 80 80 80 80 80 80 80 80 80 80 80 80 80 00 00 00 00 00 00 00 00 00 00 00 00 00 00 00 00 00 00 00 00 00 00 00 00 00 00 00 00 00 00 00 00 00 00 00 00 00 00 00 00 00 00 00 00 00 00 00 00 00 00 00 00 00 00 00 00 00 00 00 00 00 00 00 00 00 00 00 00 00 00 00 00 00 00 00 00 00 00 00 00 00 00 00 00 00 00 00 00 00 00 00 00 00 00 00 00 00 00 70 17 00 00 c0 01 56 ff ea ff 2b ff 80 02 55 ff 0c 00 09 ff eb 01 80 80 80 80 82 80 82 82 7a 75 80 80 80 80 80 80 80 80 80 80 80 80 80 80 00 00 00 00 00 00 00 00 00 00 00 00 00 00 00 00 00 00 09 00 00 00 1a 00 00 00 26 00 00 00 39 00 00 00 2a 00 00 00 1a 00 00 00 00 00 00 00 00 00 00 00 00 00 00 00 00 00 00 00 00 00 00 00 00 00 00 00 00 00 00 00 00 00 00 00 00 00 00 00 00 00 00 00 00 00 00 00 00 00 00 00 00 00 00 00 00 00 00 00 a0 0f 00 00 b7 01 66 ff e3 ff 03 ff 58 02 a5 ff f8 ff 00 ff 08 02 84 80 82 82 82 82 84 80 82 80 80 80 80 80 80 80 80 80 80 80 80 84 82 84 00 00 fd ff ff ff fd ff ff ff fd ff ff ff 00 00 00 00 01 00 00 00 17 00 00 00 2d 00 00 00 41 00 00 00 2c 00 00 00 15 00 00 00 00 00 00 00 00 00 00 00 00 00 00 00 00 00 00 00 00 00 00 00 00 00 00 00 00 00 00 00 00 00 00 00 00 00 00 00 00 00 00 00 00 00 00 00 00 00 00 00 fb ff ff ff fe ff ff ff 28 0a 00 00 40 01 21 00 9f ff 53 ff 04 02 a9 ff f6 ff fd fe 0d 02 82 82 82 84 80 80 7e 82 7e 7e 80 80 80 80 80 80 80 80 80 80 80 80 82 86 00 00 fd ff ff ff ff ff ff ff fe ff ff ff 00 00 00 00 0e 00 00 00 25 00 00 00 2d 00 00 00 3e 00 00 00 32 00 00 00 1e 00 00 00 00 00 00 00 00 00 00 00 00 00 00 00 00 00 00 00 00 00 00 00 00 00 00 00 00 00 00 00 00 00 00 00 00 00 00 00 00 00 00 00 00 00 00 00 00 00 00 00 fd ff ff ff fe ff ff ff];
		};
		iq_color {
			size = [ec 06 00 00];
			data = [00 00 00 00 80 80 40 10 00 00 00 00 00 00 00 00 00 00 00 00 00 14 0f 0a 05 00 00 00 00 00 00 00 00 00 05 0a 0f 00 00 00 80 00 00 00 80 00 00 00 80 00 00 00 80 00 00 00 80 00 00 00 80 00 00 00 80 00 00 00 80 00 00 00 80 00 00 00 80 00 00 00 80 00 00 00 80 00 00 00 80 00 00 00 80 00 00 00 80 00 00 00 80 00 00 00 80 00 00 00 c8 80 40 00 00 00 00 00 00 00 00 00 00 00 00 00 00 00 00 00 00 00 00 00 00 00 00 00 00 00 1e 3c 78 00 00 00 94 00 00 00 94 00 00 00 94 00 00 00 94 00 00 00 94 00 00 00 94 00 00 00 94 00 00 00 94 00 00 00 94 00 00 00 94 00 00 00 94 00 00 00 94 00 00 00 94 00 00 00 94 00 00 00 94 00 00 00 94 00 00 00 94 00 00 00 be 80 40 00 00 00 00 00 00 00 00 00 00 00 00 00 00 00 00 00 08 00 00 00 00 00 00 00 00 00 1e 3c 78 00 00 00 90 00 00 00 90 00 00 00 90 00 00 00 90 00 00 00 90 00 00 00 90 00 00 00 90 00 00 00 90 00 00 00 90 00 00 00 90 00 00 00 90 00 00 00 90 00 00 00 90 00 00 00 90 00 00 00 90 00 00 00 90 00 00 00 90 00 00 00 aa 80 40 00 00 00 00 00 00 00 00 00 00 00 00 00 00 00 00 00 00 00 00 00 00 00 00 00 00 00 1e 3c 78 00 00 00 8c 00 00 00 8c 00 00 00 8c 00 00 00 8c 00 00 00 8c 00 00 00 8c 00 00 00 8c 00 00 00 8c 00 00 00 8c 00 00 00 8c 00 00 00 8c 00 00 00 8c 00 00 00 8c 00 00 00 8c 00 00 00 8c 00 00 00 8c 00 00 00 8c 00 00 00 94 80 40 00 00 00 00 00 00 00 00 00 00 00 00 00 00 05 05 05 05 05 05 05 05 05 05 05 05 05 23 41 7d 00 00 00 88 00 00 00 88 00 00 00 88 00 00 00 88 00 00 00 88 00 00 00 88 00 00 00 88 00 00 00 88 00 00 00 88 00 00 00 88 00 00 00 88 00 00 00 88 00 00 00 88 00 00 00 88 00 00 00 88 00 00 00 88 00 00 00 88 00 00 00 80 8e 4e 0e 0e 0e 0e 0e 0e 0e 0e 0e 0e 0e 0e 0e 0e 0f 0f 0f 0f 0f 0f 0f 0f 0f 0f 0f 0f 0f 28 46 82 00 00 00 84 00 00 00 84 00 00 00 84 00 00 00 84 00 00 00 84 00 00 00 84 00 00 00 84 00 00 00 84 00 00 00 84 00 00 00 84 00 00 00 84 00 00 00 84 00 00 00 84 00 00 00 84 00 00 00 84 00 00 00 84 00 00 00 84 00 00 00 80 98 58 18 18 18 18 18 18 18 18 18 18 18 18 18 18 19 19 19 19 19 19 19 19 19 19 19 19 19 37 55 91 00 00 00 80 00 00 00 80 00 00 00 80 00 00 00 80 00 00 00 80 00 00 00 80 00 00 00 80 00 00 00 80 00 00 00 80 00 00 00 80 00 00 00 80 00 00 00 80 00 00 00 80 00 00 00 80 00 00 00 80 00 00 00 80 00 00 00 80 00 00 00 80 90 80 60 48 30 18 10 10 10 10 10 10 10 10 10 10 80 54 30 18 0c 06 00 00 00 00 00 00 05 0a 11 19 00 00 00 64 00 00 00 6e 00 00 00 78 00 00 00 80 00 00 00 80 00 00 00 80 00 00 00 80 00 00 00 80 00 00 00 80 00 00 00 80 00 00 00 80 00 00 00 80 00 00 00 80 00 00 00 80 00 00 00 80 00 00 00 80 00 00 00 80 00 00 00 80 80 40 10 00 00 00 00 00 00 00 00 00 00 00 00 00 14 0f 0a 05 00 00 00 00 00 00 00 00 00 05 0a 0f 00 00 00 80 00 00 00 80 00 00 00 80 00 00 00 80 00 00 00 80 00 00 00 80 00 00 00 80 00 00 00 80 00 00 00 80 00 00 00 80 00 00 00 80 00 00 00 80 00 00 00 80 00 00 00 80 00 00 00 80 00 00 00 80 00 00 00 80 00 00 00 80 80 40 10 00 00 00 00 00 00 00 00 00 00 00 00 00 14 0f 0a 05 00 00 00 00 00 00 00 00 00 05 0a 0f 00 00 00 80 00 00 00 80 00 00 00 80 00 00 00 80 00 00 00 80 00 00 00 80 00 00 00 80 00 00 00 80 00 00 00 80 00 00 00 80 00 00 00 80 00 00 00 80 00 00 00 80 00 00 00 80 00 00 00 80 00 00 00 80 00 00 00 80 00 00 00 80 80 40 10 00 00 00 00 00 00 00 00 00 00 00 00 00 14 0f 0a 05 00 00 00 00 00 00 00 00 00 05 0a 0f 00 00 00 80 00 00 00 80 00 00 00 80 00 00 00 80 00 00 00 80 00 00 00 80 00 00 00 80 00 00 00 80 00 00 00 80 00 00 00 80 00 00 00 80 00 00 00 80 00 00 00 80 00 00 00 80 00 00 00 70 00 00 00 60 00 00 00 50 00 00 00 64 80 40 10 00 00 00 00 00 00 00 00 00 00 00 00 00 14 0f 0a 05 00 00 00 00 00 00 00 00 00 05 0a 0f 00 00 00 80 00 00 00 80 00 00 00 80 00 00 00 80 00 00 00 80 00 00 00 80 00 00 00 80 00 00 00 80 00 00 00 80 00 00 00 80 00 00 00 80 00 00 00 80 00 00 00 80 00 00 00 80 00 00 00 70 00 00 00 60 00 00 00 50 00 00 00 64 80 40 10 00 00 00 00 00 00 00 00 00 00 00 00 00 14 0f 0a 05 00 00 00 00 00 00 00 00 00 05 0a 0f 00 00 00 80 00 00 00 80 00 00 00 80 00 00 00 80 00 00 00 80 00 00 00 80 00 00 00 80 00 00 00 80 00 00 00 80 00 00 00 80 00 00 00 80 00 00 00 80 00 00 00 80 00 00 00 80 00 00 00 70 00 00 00 60 00 00 00 50 00 00 00 64 80 40 10 00 00
 00 00 00 00 00 00 00 00 00 00 00 14 0f 0a 05 00 00 00 00 00 00 00 00 00 05 0a 0f 00 00 00 80 00 00 00 80 00 00 00 80 00 00 00 80 00 00 00 80 00 00 00 80 00 00 00 80 00 00 00 80 00 00 00 80 00 00 00 80 00 00 00 80 00 00 00 80 00 00 00 80 00 00 00 80 00 00 00 80 00 00 00 80 00 00 00 80 00 00 00 64 80 40 10 00 00 00 00 00 00 00 00 00 00 00 00 00 14 0f 0a 05 00 00 00 00 00 00 00 00 00 05 0a 0f 00 00 00 80 00 00 00 80 00 00 00 80 00 00 00 80 00 00 00 80 00 00 00 80 00 00 00 80 00 00 00 80 00 00 00 80 00 00 00 80 00 00 00 80 00 00 00 80 00 00 00 80 00 00 00 80 00 00 00 80 00 00 00 80 00 00 00 80 00 00 00 64 80 40 10 00 00 00 00 00 00 00 00 00 00 00 00 00 14 0f 0a 05 00 00 00 00 00 00 00 00 00 05 0a 0f 00 00 00 80 00 00 00 80 00 00 00 80 00 00 00 80 00 00 00 80 00 00 00 80 00 00 00 80 00 00 00 80 00 00 00 80 00 00 00 80 00 00 00 80 00 00 00 80 00 00 00 80 00 00 00 80 00 00 00 80 00 00 00 80 00 00 00 80 00 00 00 64 80 40 10 00 00 00 00 00 00 00 00 00 00 00 00 00 14 0f 0a 05 00 00 00 00 00 00 00 00 00 05 0a 0f 00 00 00 80 00 00 00 80 00 00 00 80 00 00 00 80 00 00 00 80 00 00 00 80 00 00 00 80 00 00 00 80 00 00 00 80 00 00 00 80 00 00 00 80 00 00 00 80 00 00 00 80 00 00 00 80 00 00 00 80 00 00 00 80 00 00 00 80 00 00 00];
		};
		iq_contrast {
			size = [b0 00 00 00];
			data = [00 00 00 00 80 00 00 00 00 00 00 00 00 00 80 19 1e 1e 23 23 23 23 23 1e 80 19 1e 1e 23 23 23 23 23 1e 80 1e 23 23 28 28 28 28 28 23 80 1e 23 23 28 28 28 28 28 23 80 1e 23 23 28 28 28 28 28 23 7f 1e 23 23 28 28 28 28 28 23 78 19 1e 1e 23 23 23 23 23 1e 84 0f 0f 0f 0f 0f 0f 0f 0f 0f 80 0a 0a 0a 0a 0a 0a 0a 0a 0a 80 0a 0a 0a 0a 0a 0a 0a 0a 0a 84 0a 0a 0a 0a 0a 0a 0a 0a 0a 84 0a 0a 0a 0a 0a 0a 0a 0a 0a 80 00 00 00 00 00 00 00 00 00 80 00 00 00 00 00 00 00 00 00 80 00 00 00 00 00 00 00 00 00 80 00 00 00 00 00 00 00 00 00 00 00];
		};
		iq_edge {
			size = [14 05 00 00];
			data = [01 00 00 00 00 00 00 00 80 00 00 00 2e 00 00 00 08 30 57 7a 9a b7 dd ff ff e0 c0 aa 9a 90 88 80 3c 3f 40 40 40 40 40 40 40 40 40 40 40 40 40 40 80 80 80 80 80 80 80 80 80 80 80 80 80 80 80 80 80 80 80 80 80 80 80 80 80 00 00 00 80 00 00 00 80 00 00 00 08 00 00 00 00 00 00 00 00 00 00 00 10 00 00 00 28 00 00 00 f0 00 00 00 00 01 00 00 00 01 00 00 00 00 00 00 80 00 00 00 00 00 00 00 02 00 00 00 00 00 00 00 00 02 00 00 00 00 00 00 05 00 00 00 96 00 00 00 96 00 00 00 10 00 00 00 00 00 00 00 00 00 00 00 10 00 00 00 23 00 00 00 4b 00 00 00 00 01 00 00 00 01 00 00 00 00 00 00 64 00 00 00 00 00 00 00 05 00 00 00 00 00 00 00 40 02 00 00 00 00 00 00 05 00 00 00 96 00 00 00 96 00 00 00 10 00 00 00 00 00 00 00 00 00 00 00 10 00 00 00 28 00 00 00 4b 00 00 00 00 01 00 00 00 01 00 00 00 00 00 00 80 00 00 00 00 00 00 00 05 00 00 00 00 00 00 00 40 02 00 00 00 00 00 00 05 00 00 00 b8 00 00 00 b8 00 00 00 10 00 00 00 00 00 00 00 02 00 00 00 0a 00 00 00 37 00 00 00 4b 00 00 00 00 01 00 00 00 01 00 00 00 00 00 00 80 00 00 00 00 00 00 00 04 00 00 00 00 00 00 00 40 02 00 00 00 00 00 00 05 00 00 00 b4 00 00 00 af 00 00 00 10 00 00 00 00 00 00 00 02 00 00 00 0c 00 00 00 3c 00 00 00 4b 00 00 00 00 01 00 00 00 01 00 00 00 00 00 00 80 00 00 00 01 00 00 00 04 00 00 00 00 00 00 00 40 02 00 00 00 00 00 00 05 00 00 00 b9 00 00 00 ba 00 00 00 10 00 00 00 00 00 00 00 02 00 00 00 0b 00 00 00 4b 00 00 00 55 00 00 00 00 01 00 00 00 01 00 00 00 00 00 00 80 00 00 00 01 00 00 00 04 00 00 00 00 00 00 00 40 02 00 00 00 00 00 00 05 00 00 00 a8 00 00 00 a8 00 00 00 10 00 00 00 00 00 00 00 03 00 00 00 0a 00 00 00 4b 00 00 00 5a 00 00 00 00 01 00 00 00 01 00 00 00 00 00 00 80 00 00 00 00 00 00 00 04 00 00 00 00 00 00 00 00 02 00 00 00 00 00 00 05 00 00 00 40 00 00 00 40 00 00 00 02 00 00 00 00 00 00 00 00 00 00 00 04 00 00 00 32 00 00 00 78 00 00 00 00 01 00 00 00 01 00 00 00 00 00 00 80 00 00 00 00 00 00 00 02 00 00 00 00 00 00 00 40 02 00 00 00 00 00 00 05 00 00 00 80 00 00 00 80 00 00 00 02 00 00 00 00 00 00 00 00 00 00 00 04 00 00 00 7e 00 00 00 33 01 00 00 00 01 00 00 00 01 00 00 00 00 00 00 80 00 00 00 02 00 00 00 02 00 00 00 00 00 00 00 00 02 00 00 00 00 00 00 05 00 00 00 80 00 00 00 80 00 00 00 00 00 00 00 00 00 00 00 00 00 00 00 04 00 00 00 a8 00 00 00 33 01 00 00 00 01 00 00 00 01 00 00 00 00 00 00 80 00 00 00 03 00 00 00 02 00 00 00 00 00 00 00 00 02 00 00 00 00 00 00 05 00 00 00 80 00 00 00 80 00 00 00 00 00 00 00 00 00 00 00 00 00 00 00 04 00 00 00 a8 00 00 00 33 01 00 00 00 01 00 00 00 01 00 00 00 00 00 00 80 00 00 00 03 00 00 00 02 00 00 00 00 00 00 00 00 02 00 00 00 00 00 00 05 00 00 00 6e 00 00 00 6e 00 00 00 00 00 00 00 00 00 00 00 00 00 00 00 04 00 00 00 4d 00 00 00 09 01 00 00 00 01 00 00 00 01 00 00 00 00 00 00 80 00 00 00 05 00 00 00 02 00 00 00 00 00 00 00 00 02 00 00 00 00 00 00 05 00 00 00 6e 00 00 00 6e 00 00 00 00 00 00 00 00 00 00 00 00 00 00 00 00 00 00 00 4d 00 00 00 09 01 00 00 00 01 00 00 00 01 00 00 00 00 00 00 80 00 00 00 05 00 00 00 02 00 00 00 00 00 00 00 00 02 00 00 00 00 00 00 05 00 00 00 60 00 00 00 60 00 00 00 00 00 00 00 00 00 00 00 00 00 00 00 04 00 00 00 a8 00 00 00 33 01 00 00 00 01 00 00 00 01 00 00 00 00 00 00 80 00 00 00 03 00 00 00 02 00 00 00 00 00 00 00 00 02 00 00 00 00 00 00 05 00 00 00 60 00 00 00 60 00 00 00 00 00 00 00 00 00 00 00 00 00 00 00 04 00 00 00 a8 00 00 00 33 01 00 00 00 01 00 00 00 01 00 00 00 00 00 00 80 00 00 00 03 00 00 00 02 00 00 00 00 00 00 00 00 02 00 00 00 00 00 00 05 00 00 00 60 00 00 00 60 00 00 00 00 00 00 00 00 00 00 00 00 00 00 00 04 00 00 00 a8 00 00 00 33 01 00 00 00 01 00 00 00 01 00 00 00 00 00 00 80 00 00 00 03 00 00 00 02 00 00 00 00 00 00 00 00 02 00 00 00 00 00 00 05 00 00 00 60 00 00 00 60 00 00 00 00 00 00 00 00 00 00 00 00 00 00 00 04 00 00 00 a8 00 00 00 33 01 00 00 00 01 00 00 00 01 00 00 00 00 00 00 80 00 00 00 03 00 00 00 02 00 00 00 00 00 00 00 00 02 00 00 00 00 00 00 05 00 00 00];
		};
		iq_3dnr {
			size = [50 1e 00 00];
			data = [01 00 00 00 00 00 00 00 40 00 00 00 40 00 00 00 00 00 00 00 80 00 00 00 80 00 00 00 80 00 00 00 c8 00 00 00 c8 00 00 00 04 00 00 00 04 00 00 00 03 00 00 00 04 00 00 00 04 00 00 00 04 00 00 00 04 00 00 00 04 00 00 00 05 00 00 00 05 00 00 00 06 00 00 00 06 00 00 00 07 00 00 00 07 00 00 00 08 00 00 00 08 00 00 00 80 00 00 00 04 00 00 00 00 00 00 00 00 00 00 00 00 00 00 00 00 00 00 00 00 00 00 00 00 00 00 00 00 00 00 00 00 00 00 00 00 00 00 00 00 00 00 00 00 00 00 00 00 00 00 00 00 00 00 00 00 00 00 00 00 00 00 00 00 00 00 00 00 00 00 00 00 00 00 00 00 00 00 00 00 00 00 00 00 00 00 00 00 00 00 00 00 00 00 00 00 00 00 00 00 00 00 00 00 00 00 00 00 00 00 00 00 00 00 00 00 00 00 00 00 00 00 00 00 00 00 00 00 00 00 00 08 00 00 00 10 00 00 00 04 00 00 00 b4 00 00 00 e6 00 00 00 06 00 00 00 01 00 00 00 01 00 00 00 10 00 00 00 20 00 00 00 30 00 00 00 40 00 00 00 80 00 00 00 40 00 00 00 00 01 00 00 00 01 00 00 10 00 00 00 10 00 00 00 10 00 00 00 10 00 00 00 10 00 00 00 10 00 00 00 10 00 00 00 10 00 00 00 10 00 00 00 10 00 00 00 10 00 00 00 10 00 00 00 08 00 00 00 10 00 00 00 40 00 00 00 40 00 00 00 10 00 00 00 08 00 00 00 08 00 00 00 10 00 00 00 18 00 00 00 20 00 00 00 00 00 00 00 06 00 00 00 0c 00 00 00 18 00 00 00 28 00 00 00 4c 00 00 00 60 00 00 00 70 00 00 00 00 00 00 00 06 00 00 00 0c 00 00 00 18 00 00 00 28 00 00 00 4c 00 00 00 60 00 00 00 70 00 00 00 80 00 00 00 40 00 00 00 40 00 00 00 40 00 00 00 00 00 00 00 5a 00 00 00 5a 00 00 00 5a 00 00 00 a0 00 00 00 a0 00 00 00 04 00 00 00 04 00 00 00 03 00 00 00 04 00 00 00 04 00 00 00 04 00 00 00 04 00 00 00 04 00 00 00 06 00 00 00 06 00 00 00 06 00 00 00 06 00 00 00 06 00 00 00 07 00 00 00 07 00 00 00 08 00 00 00 80 00 00 00 07 00 00 00 4a 01 00 00 af 00 00 00 80 00 00 00 8e 00 00 00 d1 00 00 00 e2 00 00 00 4f 00 00 00 3d 00 00 00 15 00 00 00 08 00 00 00 05 00 00 00 02 00 00 00 00 00 00 00 00 00 00 00 00 00 00 00 01 00 00 00 10 00 00 00 71 00 00 00 68 00 00 00 7f 00 00 00 d1 00 00 00 e2 00 00 00 4f 00 00 00 2c 00 00 00 3d 00 00 00 32 00 00 00 23 00 00 00 2d 00 00 00 24 00 00 00 25 00 00 00 1e 00 00 00 1c 00 00 00 08 00 00 00 10 00 00 00 03 00 00 00 b4 00 00 00 e6 00 00 00 03 00 00 00 01 00 00 00 01 00 00 00 1a 00 00 00 2a 00 00 00 54 00 00 00 80 00 00 00 20 00 00 00 08 00 00 00 14 00 00 00 a0 00 00 00 10 00 00 00 10 00 00 00 18 00 00 00 18 00 00 00 0c 00 00 00 0c 00 00 00 0c 00 00 00 0c 00 00 00 0c 00 00 00 0c 00 00 00 0c 00 00 00 0c 00 00 00 00 00 00 00 02 00 00 00 00 00 00 00 0a 00 00 00 02 00 00 00 00 00 00 00 08 00 00 00 10 00 00 00 18 00 00 00 1c 00 00 00 00 00 00 00 0e 00 00 00 1e 00 00 00 30 00 00 00 40 00 00 00 50 00 00 00 60 00 00 00 70 00 00 00 00 00 00 00 0d 00 00 00 1e 00 00 00 30 00 00 00 40 00 00 00 50 00 00 00 60 00 00 00 70 00 00 00 40 00 00 00 20 00 00 00 50 00 00 00 50 00 00 00 00 00 00 00 78 00 00 00 78 00 00 00 78 00 00 00 dc 00 00 00 dc 00 00 00 04 00 00 00 04 00 00 00 03 00 00 00 04 00 00 00 04 00 00 00 04 00 00 00 04 00 00 00 04 00 00 00 06 00 00 00 06 00 00 00 06 00 00 00 06 00 00 00 06 00 00 00 07 00 00 00 07 00 00 00 08 00 00 00 80 00 00 00 06 00 00 00 23 01 00 00 92 00 00 00 6d 00 00 00 4a 00 00 00 53 00 00 00 6e 00 00 00 fa 00 00 00 3d 00 00 00 14 00 00 00 09 00 00 00 04 00 00 00 05 00 00 00 04 00 00 00 06 00 00 00 04 00 00 00 04 00 00 00 29 00 00 00 62 00 00 00 5e 00 00 00 3f 00 00 00 48 00 00 00 59 00 00 00 cf 00 00 00 1f 00 00 00 46 00 00 00 23 00 00 00 1d 00 00 00 17 00 00 00 1c 00 00 00 1b 00 00 00 2a 00 00 00 23 00 00 00 08 00 00 00 10 00 00 00 03 00 00 00 b4 00 00 00 e6 00 00 00 03 00 00 00 01 00 00 00 01 00 00 00 20 00 00 00 40 00 00 00 54 00 00 00 60 00 00 00 20 00 00 00 08 00 00 00 64 00 00 00 a0 00 00 00 10 00 00 00 10 00 00 00 18 00 00 00 18 00 00 00 10 00 00 00 10 00 00 00 10 00 00 00 10 00 00 00 10 00 00 00 10 00 00 00 10 00 00 00 10 00 00 00 00 00 00 00 02 00 00 00 00 00 00 00 0c 00 00 00 06 00 00 00 00 00 00 00 08 00 00 00 10 00 00 00 18 00 00 00 1c 00 00 00 00 00 00 00 0e 00 00 00 1e 00 00 00 2a 00 00 00 40 00 00 00 50 00 00 00 60 00 00 00 70 00 00 00 00 00 00 00 0d 00 00 00 1c 00 00 00 30 00 00 00 40 00 00 00 50 00 00 00 60 00 00 00 70 00 00 00 40 00 00 00 20 00 00 00 64 00 00 00 64 00 00 00 00 00 00 00 b4 00 00 00 b4 00 00 00 8c 00 00 00 2c 01 00 00 2c 01 00 00 04 00 00 00 04 00 00 00 03 00 00 00 04 00 00 00 04 00 00 00 04 00 00 00 04 00 00 00 04 00 00 00 06 00 00 00 06 00 00 00 06 00 00 00 06 00 00 00 06 00 00 00 07 00 00 00 07 00 00 00 08 00 00 00 a0 00 00 00 05 00 00 00 98 02 00 00 03 01 00 00 9f 00 00 00 98 00 00 00 a6 00 00 00 28 01 00 00 b7 00 00 00 46 00 00 00 1a 00 00 00 11 00 00 00 0a 00 00 00 07 00 00 00 08 00 00 00 03 00 00 00 02 00 00 00 02 00 00 00 03 00 00 00 61 00 00 00 6a 00 00 00 74 00 00 00 76 00 00 00 fe 00 00 00 90 00 00 00 23 00 00 00 59 00 00 00 2f 00 00 00 28 00 00 00 29 00 00 00 30 00 00 00 34 00 00 00 29 00 00 00 1f 00 00 00 08 00 00 00 10 00 00 00 03 00 00 00 b4 00 00 00 e6 00 00 00 03 00 00 00 01 00 00 00 01 00 00 00 20 00 00 00 36 00 00 00 54 00 00 00 6c 00 00 00 20 00 00 00 08 00 00 00 96 00 00 00 dc 00 00 00 10 00 00 00 10 00 00 00 18 00 00 00 18 00 00 00 18 00 00 00 18 00 00 00 18 00 00 00 10 00 00 00 10 00 00 00 10 00 00 00 10 00 00 00 10 00 00 00 00 00 00 00 00 00 00 00 00 00 00 00 0c 00 00 00 04 00 00 00 00 00 00 00 08 00 00 00 10 00 00 00 18 00 00 00 1c 00 00 00 00 00 00 00 0e 00 00 00 1d 00 00 00 2a 00 00 00 40 00 00 00 50 00 00 00 60 00 00 00 70 00 00 00 00 00 00 00 0d 00 00 00 15 00 00 00 1e 00 00 00 23 00 00 00 3e 00 00 00 60 00 00 00 70 00 00 00 40 00 00 00 20 00 00 00 96 00 00 00 96 00 00 00 00 00 00 00 e6 00 00 00 e6 00 00 00 e6 00 00 00 90 01 00 00 90 01 00 00 04 00 00 00 04 00 00 00 03 00 00 00 04 00 00 00 04 00 00 00 04 00 00 00 04 00 00 00 04 00 00 00 06 00 00 00 06 00 00 00 06 00 00 00 06 00 00 00 06 00 00 00 07 00 00 00 07 00 00 00 08 00 00 00 80 00 00 00 05 00 00 00 8a 03 00 00 d3 00 00 00 b8 00 00 00 90 00 00 00 98 00 00 00 0f 01 00 00 18 01 00 00 18 01 00 00 0d 00 00 00 14 00 00 00 0a 00 00 00 09 00 00 00 0a 00 00 00 08 00 00 00 02 00 00 00 02 00 00 00 b6 01 00 00 3a 00 00 00 7b 00 00 00 64 00 00 00 62 00 00 00 b4 00 00 00 c6 00 00 00 c6 00 00 00 5b 00 00 00 2c 00 00 00 23 00 00 00 29 00 00 00 2a 00 00 00 34 00 00 00 46 00 00 00 46 00 00 00 08 00 00 00 10 00 00 00 03 00 00 00 b4 00 00 00 e6 00 00 00 03 00 00 00 01 00 00 00 01 00 00 00 30 00 00 00 40 00 00 00 60 00 00 00 80 00 00 00 28 00 00 00 0c 00 00 00 b4 00 00 00 0e 01 00 00 10 00 00 00 10 00 00 00 18 00 00 00 18 00 00 00 14 00 00 00 14 00 00 00 14 00 00 00 14 00 00 00 14 00 00 00 14 00 00 00 14 00 00 00 14 00 00 00 00 00 00 00 00 00 00 00 00 00 00 00 10 00 00 00 04 00 00 00 00 00 00 00 08 00 00 00 10 00 00 00 18 00 00 00 1c 00 00 00 00 00 00 00 0d 00 00 00 1c 00 00 00 2a 00 00 00 40 00 00 00 50 00 00 00 60 00 00 00 70 00 00 00 00 00 00 00 0d 00 00 00 15 00 00 00 1e 00 00 00 23 00 00 00 29 00 00 00 60 00 00 00 70 00 00 00 40 00 00 00 20 00 00 00 96 00 00 00 96 00 00 00 00 00 00 00 5e 01 00 00 5e 01 00 00 5e 01 00 00 f4 01 00 00 f4 01 00 00 04 00 00 00 04 00 00 00 03 00 00 00 04 00 00 00 04 00 00 00 04 00 00 00 05 00 00 00 05 00 00 00 06 00 00 00 06 00 00 00 06 00 00 00 06 00 00 00 06 00 00 00 07 00 00 00 07 00 00 00 08 00 00 00 80 00 00 00 04 00 00 00 68 03 00 00 e9 00 00 00 b9 00 00 00 c2 00 00 00 10 01 00 00 93 01 00 00 c1 01 00 00 69 00 00 00 0e 00 00 00 15 00 00 00 0e 00 00 00 0c 00 00 00 0b 00 00 00 06 00 00 00 03 00 00 00 05 00 00 00 f4 01 00 00 b0 00 00 00 d3 00 00 00 e3 00 00 00 12 01 00 00 92 01 00 00 cb 01 00 00 8e 00 00 00 58 00 00 00 2c 00 00 00 25 00 00 00 2d 00 00 00 38 00 00 00 4d 00 00 00 53 00 00 00 2c 00 00 00 08 00 00 00 10 00 00 00 03 00 00 00 b4 00 00 00 e6 00 00 00 03 00 00 00 01 00 00 00 01 00 00 00 30 00 00 00 40 00 00 00 60 00 00 00 80 00 00 00 28 00 00 00 10 00 00 00 dc 00 00 00 40 01 00 00 14 00 00 00 14 00 00 00 1c 00 00 00 1c 00 00 00 14 00 00 00 14 00 00 00 14 00 00 00 14 00 00 00 18 00 00 00 18 00 00 00 18 00 00 00 18 00 00 00 00 00 00 00 00 00 00 00 00 00 00 00 10 00 00 00 06 00 00 00 00 00 00 00 08 00 00 00 10 00 00 00 18 00 00 00 1c 00 00 00 00 00 00 00 0d 00 00 00 18 00 00 00 28 00 00 00 38 00 00 00 50 00 00 00 60 00 00 00 70 00 00 00 00 00 00 00 0d 00 00 00 15 00 00 00 1e 00 00 00 23 00 00 00 29 00 00 00 31 00 00 00 3c 00 00 00 40 00 00 00 20 00 00 00 c8 00 00 00 c8 00 00 00 00 00 00 00 a4 01 00 00 a4 01 00 00 a4 01 00 00 8a 02 00 00 8a 02 00 00 04 00 00 00 04 00 00 00 03 00 00 00 04 00 00 00 04 00 00 00 04 00 00 00 05 00 00 00 05 00 00 00 06 00 00 00 06 00 00 00 06 00 00 00 06 00 00 00 06 00 00 00 07 00 00 00 07 00 00 00 08 00 00 00 80 00 00 00 03 00 00 00 7b 02 00 00 d7 01 00 00 4e 02 00 00 03 03 00 00 06 03 00 00 6c 03 00 00 cb 01 00 00 29 00 00 00 12 00 00 00 12 00 00 00 11 00 00 00 0b 00 00 00 0b 00 00 00 05 00 00 00 06 00 00 00 0d 00 00 00 ea 00 00 00 b9 00 00 00 00 01 00 00 d9 01 00 00 b1 01 00 00 a8 02 00 00 b4 00 00 00 25 00 00 00 4b 00 00 00 3e 00 00 00 4f 00 00 00 60 00 00 00 57 00 00 00 5f 00 00 00 60 00 00 00 12 00 00 00 08 00 00 00 10 00 00 00 03 00 00 00 b4 00 00 00 e6 00 00 00 03 00 00 00 01 00 00 00 01 00 00 00 30 00 00 00 40 00 00 00 60 00 00 00 80 00 00 00 30 00 00 00 20 00 00 00 fa 00 00 00 5e 01 00 00 18 00 00 00 18 00 00 00 24 00 00 00 28 00 00 00 14 00 00 00 14 00 00 00 14 00 00 00 14 00 00 00 14 00 00 00 18 00 00 00 18 00 00 00 18 00 00 00 08 00 00 00 08 00 00 00 04 00 00 00 14 00 00 00 0c 00 00 00 08 00 00 00 08 00 00 00 10 00 00 00 18 00 00 00 1c 00 00 00 00 00 00 00 0d 00 00 00 18 00 00 00 28 00 00 00 38 00 00 00 50 00 00 00 60 00 00 00 70 00 00 00 00 00 00 00 0d 00 00 00 15 00 00 00 1e 00 00 00 23 00 00 00 29 00 00 00 31 00 00 00 3c 00 00 00 60 00 00 00 30 00 00 00 96 00 00 00 96 00 00 00 00 00 00 00 5e 01 00 00 5e 01 00 00 5e 01 00 00 26 02 00 00 26 02 00 00 04 00 00 00 04 00 00 00 03 00 00 00 04 00 00 00 04 00 00 00 04 00 00 00 04 00 00 00 04 00 00 00 06 00 00 00 06 00 00 00 06 00 00 00 06 00 00 00 06 00 00 00 07 00 00 00 07 00 00 00 08 00 00 00 9e 00 00 00 05 00 00 00 50 00 00 00 50 00 00 00 50 00 00 00 50 00 00 00 b4 00 00 00 d4 03 00 00 d4 03 00 00 d4 03 00 00 14 00 00 00 13 00 00 00 14 00 00 00 1c 00 00 00 15 00 00 00 15 00 00 00 15 00 00 00 15 00 00 00 78 00 00 00 78 00 00 00 82 00 00 00 82 00 00 00 82 00 00 00 82 00 00 00 82 00 00 00 82 00 00 00 32 00 00 00 3c 00 00 00 40 00 00 00 42 00 00 00 44 00 00 00 44 00 00 00 46 00 00 00 46 00 00 00 08 00 00 00 10 00 00 00 03 00 00 00 b4 00 00 00 e6 00 00 00 03 00 00 00 01 00 00 00 01 00 00 00 40 00 00 00 50 00 00 00 64 00 00 00 64 00 00 00 40 00 00 00 20 00 00 00 e8 03 00 00 e8 03 00 00 10 00 00 00 10 00 00 00 20 00 00 00 20 00 00 00 10 00 00 00 10 00 00 00 10 00 00 00 10 00 00 00 10 00 00 00 10 00 00 00 10 00 00 00 10 00 00 00 00 00 00 00 96 00 00 00 c8 00 00 00 ff 00 00 00 40 00 00 00 00 00 00 00 08 00 00 00 10 00 00 00 18 00 00 00 1c 00 00 00 00 00 00 00 08 00 00 00 0e 00 00 00 15 00 00 00 20 00 00 00 24 00 00 00 2f 00 00 00 3a 00 00 00 00 00 00 00 08 00 00 00 0d 00 00 00 0e 00 00 00 13 00 00 00 15 00 00 00 16 00 00 00 1c 00 00 00 80 00 00 00 40 00 00 00 96 00 00 00 96 00 00 00 00 00 00 00 5e 01 00 00 5e 01 00 00 5e 01 00 00 26 02 00 00 26 02 00 00 04 00 00 00 04 00 00 00 03 00 00 00 04 00 00 00 04 00 00 00 04 00 00 00 04 00 00 00 04 00 00 00 06 00 00 00 06 00 00 00 06 00 00 00 06 00 00 00 06 00 00 00 07 00 00 00 07 00 00 00 08 00 00 00 9e 00 00 00 05 00 00 00 90 01 00 00 90 01 00 00 90 01 00 00 90 01 00 00 f4 01 00 00 14 05 00 00 14 05 00 00 14 05 00 00 14 00 00 00 13 00 00 00 14 00 00 00 1c 00 00 00 15 00 00 00 15 00 00 00 15 00 00 00 15 00 00 00 78 00 00 00 78 00 00 00 82 00 00 00 82 00 00 00 82 00 00 00 82 00 00 00 82 00 00 00 82 00 00 00 32 00 00 00 3c 00 00 00 40 00 00 00 42 00 00 00 44 00 00 00 44 00 00 00 46 00 00 00 46 00 00 00 08 00 00 00 10 00 00 00 03 00 00 00 b4 00 00 00 e6 00 00 00 03 00 00 00 01 00 00 00 01 00 00 00 40 00 00 00 50 00 00 00 64 00 00 00 64 00 00 00 80 00 00 00 40 00 00 00 e8 03 00 00 e8 03 00 00 10 00 00 00 10 00 00 00 20 00 00 00 20 00 00 00 10 00 00 00 10 00 00 00 10 00 00 00 10 00 00 00 10 00 00 00 10 00 00 00 10 00 00 00 10 00 00 00 00 00 00 00 96 00 00 00 c8 00 00 00 ff 00 00 00 40 00 00 00 00 00 00 00 08 00 00 00 10 00 00 00 18 00 00 00 1c 00 00 00 00 00 00 00 08 00 00 00 0e 00 00 00 15 00 00 00 20 00 00 00 24 00 00 00 2f 00 00 00 3a 00 00 00 00 00 00 00 08 00 00 00 0d 00 00 00 0e 00 00 00 13 00 00 00 15 00 00 00 16 00 00 00 1c 00 00 00 80 00 00 00 40 00 00 00 96 00 00 00 96 00 00 00 00 00 00 00 5e 01 00 00 5e 01 00 00 5e 01 00 00 26 02 00 00 26 02 00 00 04 00 00 00 04 00 00 00 03 00 00 00 04 00 00 00 04 00 00 00 04 00 00 00 04 00 00 00 04 00 00 00 06 00 00 00 06 00 00 00 06 00 00 00 06 00 00 00 06 00 00 00 07 00 00 00 07 00 00 00 08 00 00 00 9e 00 00 00 03 00 00 00 90 01 00 00 90 01 00 00 90 01 00 00 90 01 00 00 f4 01 00 00 14 05 00 00 14 05 00 00 14 05 00 00 1e 00 00 00 23 00 00 00 19 00 00 00 1c 00 00 00 23 00 00 00 23 00 00 00 22 00 00 00 22 00 00 00 64 00 00 00 64 00 00 00 82 00 00 00 82 00 00 00 82 00 00 00 82 00 00 00 82 00 00 00 82 00 00 00 32 00 00 00 3c 00 00 00 40 00 00 00 42 00 00 00 44 00 00 00 44 00 00 00 46 00 00 00 46 00 00 00 08 00 00 00 10 00 00 00 03 00 00 00 b4 00 00 00 e6 00 00 00 03 00 00 00 01 00 00 00 01 00 00 00 00 00 00 00 00 00 00 00 00 00 00 00 00 00 00 00 80 00 00 00 40 00 00 00 08 07 00 00 b8 0b 00 00 10 00 00 00 10 00 00 00 20 00 00 00 20 00 00 00 10 00 00 00 10 00 00 00 10 00 00 00 10 00 00 00 10 00 00 00 10 00 00 00 10 00 00 00 10 00 00 00 00 00 00 00 50 00 00 00 c8 00 00 00 c8 00 00 00 40 00 00 00 00 00 00 00 08 00 00 00 10 00 00 00 18 00 00 00 1c 00 00 00 00 00 00 00 00 00 00 00 08 00 00 00 10 00 00 00 20 00 00 00 30 00 00 00 40 00 00 00 50 00 00 00 00 00 00 00 08 00 00 00 0d 00 00 00 0e 00 00 00 13 00 00 00 15 00 00 00 16 00 00 00 1c 00 00 00 80 00 00 00 40 00 00 00 2c 01 00 00 2c 01 00 00 00 00 00 00 58 02 00 00 58 02 00 00 58 02 00 00 20 03 00 00 20 03 00 00 03 00 00 00 03 00 00 00 03 00 00 00 03 00 00 00 03 00 00 00 03 00 00 00 03 00 00 00 03 00 00 00 04 00 00 00 05 00 00 00 06 00 00 00 06 00 00 00 06 00 00 00 07 00 00 00 07 00 00 00 08 00 00 00 80 00 00 00 04 00 00 00 90 01 00 00 90 01 00 00 90 01 00 00 90 01 00 00 f4 01 00 00 f4 01 00 00 f4 01 00 00 f4 01 00 00 1c 00 00 00 1d 00 00 00 1d 00 00 00 1d 00 00 00 19 00 00 00 19 00 00 00 19 00 00 00 19 00 00 00 64 00 00 00 64 00 00 00 78 00 00 00 78 00 00 00 82 00 00 00 82 00 00 00 82 00 00 00 82 00 00 00 32 00 00 00 3c 00 00 00 40 00 00 00 42 00 00 00 44 00 00 00 44 00 00 00 46 00 00 00 46 00 00 00 0a 00 00 00 0e 00 00 00 03 00 00 00 b4 00 00 00 e6 00 00 00 03 00 00 00 01 00 00 00 01 00 00 00 3c 00 00 00 3c 00 00 00 5a 00 00 00 5a 00 00 00 20 00 00 00 10 00 00 00 08 07 00 00 b8 0b 00 00 10 00 00 00 10 00 00 00 20 00 00 00 20 00 00 00 10 00 00 00 10 00 00 00 10 00 00 00 10 00 00 00 10 00 00 00 10 00 00 00 10 00 00 00 10 00 00 00 00 00 00 00 50 00 00 00 78 00 00 00 c8 00 00 00 18 00 00 00 00 00 00 00 08 00 00 00 10 00 00 00 18 00 00 00 1c 00 00 00 00 00 00 00 05 00 00 00 0b 00 00 00 13 00 00 00 1b 00 00 00 1e 00 00 00 29 00 00 00 32 00 00 00 00 00 00 00 08 00 00 00 0d 00 00 00 0e 00 00 00 13 00 00 00 15 00 00 00 16 00 00 00 1c 00 00 00 80 00 00 00 40 00 00 00 c8 00 00 00 c8 00 00 00 00 00 00 00 90 01 00 00 90 01 00 00 90 01 00 00 58 02 00 00 58 02 00 00 03 00 00 00 03 00 00 00 02 00 00 00 03 00 00 00 03 00 00 00 03 00 00 00 03 00 00 00 03 00 00 00 04 00 00 00 05 00 00 00 06 00 00 00 06 00 00 00 06 00 00 00 07 00 00 00 07 00 00 00 08 00 00 00 80 00 00 00 04 00 00 00 90 01 00 00 90 01 00 00 90 01 00 00 90 01 00 00 f4 01 00 00 f4 01 00 00 f4 01 00 00 f4 01 00 00 19 00 00 00 1b 00 00 00 1c 00 00 00 1c 00 00 00 19 00 00 00 19 00 00 00 19 00 00 00 19 00 00 00 78 00 00 00 64 00 00 00 78 00 00 00 78 00 00 00 82 00 00 00 82 00 00 00 82 00 00 00 82 00 00 00 46 00 00 00 50 00 00 00 50 00 00 00 50 00 00 00 50 00 00 00 46 00 00 00 46 00 00 00 46 00 00 00 0a 00 00 00 0e 00 00 00 05 00 00 00 b4 00 00 00 e6 00 00 00 04 00 00 00 01 00 00 00 01 00 00 00 3c 00 00 00 3c 00 00 00 5a 00 00 00 5a 00 00 00 20 00 00 00 10 00 00 00 08 07 00 00 b8 0b 00 00 10 00 00 00 10 00 00 00 20 00 00 00 20 00 00 00 10 00 00 00 10 00 00 00 10 00 00 00 10 00 00 00 10 00 00 00 10 00 00 00 10 00 00 00 10 00 00 00 00 00 00 00 50 00 00 00 78 00 00 00 c8 00 00 00 18 00 00 00 00 00 00 00 08 00 00 00 10 00 00 00 18 00 00 00 1c 00 00 00 00 00 00 00 05 00 00 00 0b 00 00 00 13 00 00 00 1b 00 00 00 1e 00 00 00 29 00 00 00 32 00 00 00 00 00 00 00 08 00 00 00 0d 00 00 00 0e 00 00 00 13 00 00 00 15 00 00 00 16 00 00 00 1c 00 00 00 80 00 00 00 40 00 00 00 c8 00 00 00 c8 00 00 00 00 00 00 00 90 01 00 00 90 01 00 00 90 01 00 00 58 02 00 00 58 02 00 00 03 00 00 00 03 00 00 00 03 00 00 00 03 00 00 00 03 00 00 00 03 00 00 00 03 00 00 00 03 00 00 00 07 00 00 00 05 00 00 00 05 00 00 00 05 00 00 00 0f 00 00 00 0f 00 00 00 0f 00 00 00 0f 00 00 00 af 00 00 00 03 00 00 00 00 04 00 00 4c 04 00 00 b0 04 00 00 14 05 00 00 14 05 00 00 14 05 00 00 14 05 00 00 14 05 00 00 19 00 00 00 32 00 00 00 32 00 00 00 32 00 00 00 23 00 00 00 23 00 00 00 14 00 00 00 14 00 00 00 50 00 00 00 6e 00 00 00 6e 00 00 00 6e 00 00 00 8c 00 00 00 96 00 00 00 a0 00 00 00 a0 00 00 00 3c 00 00 00 5a 00 00 00 5a 00 00 00 5a 00 00 00 44 00 00 00 50 00 00 00 50 00 00 00 5a 00 00 00 10 00 00 00 14 00 00 00 03 00 00 00 b4 00 00 00 c8 00 00 00 04 00 00 00 01 00 00 00 01 00 00 00 8c 00 00 00 96 00 00 00 a0 00 00 00 aa 00 00 00 80 00 00 00 40 00 00 00 b8 0b 00 00 70 17 00 00 10 00 00 00 10 00 00 00 20 00 00 00 20 00 00 00 10 00 00 00 10 00 00 00 10 00 00 00 10 00 00 00 10 00 00 00 10 00 00 00 10 00 00 00 10 00 00 00 00 00 00 00 40 00 00 00 80 00 00 00 ff 00 00 00 10 00 00 00 06 00 00 00 10 00 00 00 20 00 00 00 30 00 00 00 3f 00 00 00 00 00 00 00 06 00 00 00 0d 00 00 00 15 00 00 00 1c 00 00 00 26 00 00 00 2f 00 00 00 3a 00 00 00 00 00 00 00 06 00 00 00 0b 00 00 00 0b 00 00 00 13 00 00 00 18 00 00 00 21 00 00 00 34 00 00 00 80 00 00 00 40 00 00 00 80 00 00 00 80 00 00 00 00 00 00 00 00 01 00 00 00 01 00 00 00 01 00 00 00 02 00 00 00 02 00 00 04 00 00 00 04 00 00 00 03 00 00 00 04 00 00 00 04 00 00 00 04 00 00 00 04 00 00 00 04 00 00 00 08 00 00 00 09 00 00 00 09 00 00 00 0a 00 00 00 0a 00 00 00 0a 00 00 00 0b 00 00 00 0b 00 00 00 96 00 00 00 03 00 00 00 00 02 00 00 00 02 00 00 00 02 00 00 00 02 00 00 00 02 00 00 00 02 00 00 00 02 00 00 00 02 00 00 18 00 00 00 18 00 00 00 17 00 00 00 15 00 00 00 16 00 00 00 16 00 00 00 16 00 00 00 16 00 00 00 5a 00 00 00 5a 00 00 00 5a 00 00 00 5a 00 00 00 5a 00 00 00 5a 00 00 00 5a 00 00 00 5a 00 00 00 3c 00 00 00 3c 00 00 00 3c 00 00 00 3c 00 00 00 3c 00 00 00 3c 00 00 00 3c 00 00 00 3c 00 00 00 08 00 00 00 10 00 00 00 14 00 00 00 b4 00 00 00 e6 00 00 00 02 00 00 00 01 00 00 00 01 00 00 00 64 00 00 00 6e 00 00 00 78 00 00 00 82 00 00 00 80 00 00 00 40 00 00 00 b0 04 00 00 d0 07 00 00 14 00 00 00 10 00 00 00 10 00 00 00 10 00 00 00 14 00 00 00 18 00 00 00 18 00 00 00 10 00 00 00 10 00 00 00 10 00 00 00 10 00 00 00 10 00 00 00 00 00 00 00 20 00 00 00 80 00 00 00 ff 00 00 00 20 00 00 00 02 00 00 00 10 00 00 00 20 00 00 00 30 00 00 00 3f 00 00 00 00 00 00 00 01 00 00 00 01 00 00 00 01 00 00 00 01 00 00 00 02 00 00 00 03 00 00 00 04 00 00 00 00 00 00 00 06 00 00 00 0b 00 00 00 0b 00 00 00 13 00 00 00 18 00 00 00 21 00 00 00 34 00 00 00 80 00 00 00 40 00 00 00 80 00 00 00 80 00 00 00 00 00 00 00 00 01 00 00 00 01 00 00 00 01 00 00 00 02 00 00 00 02 00 00 04 00 00 00 04 00 00 00 03 00 00 00 04 00 00 00 04 00 00 00 04 00 00 00 04 00 00 00 04 00 00 00 08 00 00 00 09 00 00 00 09 00 00 00 0a 00 00 00 0a 00 00 00 0a 00 00 00 0b 00 00 00 0b 00 00 00 96 00 00 00 03 00 00 00 00 02 00 00 00 02 00 00 00 02 00 00 00 02 00 00 00 02 00 00 00 02 00 00 00 02 00 00 00 02 00 00 18 00 00 00 18 00 00 00 17 00 00 00 15 00 00 00 16 00 00 00 16 00 00 00 16 00 00 00 16 00 00 00 5a 00 00 00 5a 00 00 00 5a 00 00 00 5a 00 00 00 5a 00 00 00 5a 00 00 00 5a 00 00 00 5a 00 00 00 3c 00 00 00 3c 00 00 00 3c 00 00 00 3c 00 00 00 3c 00 00 00 3c 00 00 00 3c 00 00 00 3c 00 00 00 08 00 00 00 10 00 00 00 14 00 00 00 b4 00 00 00 e6 00 00 00 02 00 00 00 01 00 00 00 01 00 00 00 64 00 00 00 6e 00 00 00 78 00 00 00 82 00 00 00 80 00 00 00 40 00 00 00 b0 04 00 00 d0 07 00 00 14 00 00 00 10 00 00 00 10 00 00 00 10 00 00 00 14 00 00 00 18 00 00 00 18 00 00 00 10 00 00 00 10 00 00 00 10 00 00 00 10 00 00 00 10 00 00 00 00 00 00 00 20 00 00 00 80 00 00 00 ff 00 00 00 20 00 00 00 02 00 00 00 10 00 00 00 20 00 00 00 30 00 00 00 3f 00 00 00 00 00 00 00 01 00 00 00 01 00 00 00 01 00 00 00 01 00 00 00 02 00 00 00 03 00 00 00 04 00 00 00 00 00 00 00 06 00 00 00 0b 00 00 00 0b 00 00 00 13 00 00 00 18 00 00 00 21 00 00 00 34 00 00 00 80 00 00 00 40 00 00 00 80 00 00 00 80 00 00 00 00 00 00 00 00 01 00 00 00 01 00 00 00 01 00 00 00 02 00 00 00 02 00 00 04 00 00 00 04 00 00 00 03 00 00 00 04 00 00 00 04 00 00 00 04 00 00 00 04 00 00 00 04 00 00 00 08 00 00 00 09 00 00 00 09 00 00 00 0a 00 00 00 0a 00 00 00 0a 00 00 00 0b 00 00 00 0b 00 00 00 96 00 00 00 03 00 00 00 00 02 00 00 00 02 00 00 00 02 00 00 00 02 00 00 00 02 00 00 00 02 00 00 00 02 00 00 00 02 00 00 18 00 00 00 18 00 00 00 17 00 00 00 15 00 00 00 16 00 00 00 16 00 00 00 16 00 00 00 16 00 00 00 5a 00 00 00 5a 00 00 00 5a 00 00 00 5a 00 00 00 5a 00 00 00 5a 00 00 00 5a 00 00 00 5a 00 00 00 3c 00 00 00 3c 00 00 00 3c 00 00 00 3c 00 00 00 3c 00 00 00 3c 00 00 00 3c 00 00 00 3c 00 00 00 08 00 00 00 10 00 00 00 14 00 00 00 b4 00 00 00 e6 00 00 00 02 00 00 00 01 00 00 00 01 00 00 00 64 00 00 00 6e 00 00 00 78 00 00 00 82 00 00 00 80 00 00 00 40 00 00 00 b0 04 00 00 d0 07 00 00 14 00 00 00 10 00 00 00 10 00 00 00 10 00 00 00 14 00 00 00 18 00 00 00 18 00 00 00 10 00 00 00 10 00 00 00 10 00 00 00 10 00 00 00 10 00 00 00 00 00 00 00 20 00 00 00 80 00 00 00 ff 00 00 00 20 00 00 00 02 00 00 00 10 00 00 00 20 00 00 00 30 00 00 00 3f 00 00 00 00 00 00 00 01 00 00 00 01 00 00 00 01 00 00 00 01 00 00 00 02 00 00 00 03 00 00 00 04 00 00 00 00 00 00 00 06 00 00 00 0b 00 00 00 0b 00 00 00 13 00 00 00 18 00 00 00 21 00 00 00 34 00 00 00 80 00 00 00 40 00 00 00 80 00 00 00 80 00 00 00 00 00 00 00 00 01 00 00 00 01 00 00 00 01 00 00 00 02 00 00 00 02 00 00 04 00 00 00 04 00 00 00 03 00 00 00 04 00 00 00 04 00 00 00 04 00 00 00 04 00 00 00 04 00 00 00 08 00 00 00 09 00 00 00 09 00 00 00 0a 00 00 00 0a 00 00 00 0a 00 00 00 0b 00 00 00 0b 00 00 00 96 00 00 00 03 00 00 00 00 02 00 00 00 02 00 00 00 02 00 00 00 02 00 00 00 02 00 00 00 02 00 00 00 02 00 00 00 02 00 00 18 00 00 00 18 00 00 00 17 00 00 00 15 00 00 00 16 00 00 00 16 00 00 00 16 00 00 00 16 00 00 00 5a 00 00 00 5a 00 00 00 5a 00 00 00 5a 00 00 00 5a 00 00 00 5a 00 00 00 5a 00 00 00 5a 00 00 00 3c 00 00 00 3c 00 00 00 3c 00 00 00 3c 00 00 00 3c 00 00 00 3c 00 00 00 3c 00 00 00 3c 00 00 00 08 00 00 00 10 00 00 00 14 00 00 00 b4 00 00 00 e6 00 00 00 02 00 00 00 01 00 00 00 01 00 00 00 64 00 00 00 6e 00 00 00 78 00 00 00 82 00 00 00 80 00 00 00 40 00 00 00 b0 04 00 00 d0 07 00 00 14 00 00 00 10 00 00 00 10 00 00 00 10 00 00 00 14 00 00 00 18 00 00 00 18 00 00 00 10 00 00 00 10 00 00 00 10 00 00 00 10 00 00 00 10 00 00 00 00 00 00 00 20 00 00 00 80 00 00 00 ff 00 00 00 20 00 00 00 02 00 00 00 10 00 00 00 20 00 00 00 30 00 00 00 3f 00 00 00 00 00 00 00 01 00 00 00 01 00 00 00 01 00 00 00 01 00 00 00 02 00 00 00 03 00 00 00 04 00 00 00 00 00 00 00 06 00 00 00 0b 00 00 00 0b 00 00 00 13 00 00 00 18 00 00 00 21 00 00 00 34 00 00 00 80 00 00 00 40 00 00 00];
		};
		iq_pfr {
			size = [d8 00 00 00];
			data = [00 00 00 00 00 00 00 00 00 00 00 00 00 00 00 00 00 00 00 00 08 00 00 00 70 00 00 00 e8 00 00 00 ff 00 00 00 ff 00 00 00 ff 00 00 00 ff 00 00 00 ff 00 00 00 ff 00 00 00 ff 00 00 00 af 00 00 00 91 00 00 00 01 00 00 00 91 00 00 00 af 00 00 00 e0 00 00 00 2c 01 00 00 e0 00 00 00 2c 01 00 00 e0 00 00 00 2c 01 00 00 e0 00 00 00 2c 01 00 00 e0 00 00 00 2c 01 00 00 e0 00 00 00 2c 01 00 00 e0 00 00 00 2c 01 00 00 e0 00 00 00 2c 01 00 00 e0 00 00 00 2c 01 00 00 e0 00 00 00 2c 01 00 00 e0 00 00 00 2c 01 00 00 e0 00 00 00 2c 01 00 00 e0 00 00 00 2c 01 00 00 e0 00 00 00 2c 01 00 00 e0 00 00 00 2c 01 00 00 e0 00 00 00 2c 01 00 00 e0 00 00 00 2c 01 00 00];
		};
		iq_wdr {
			size = [e4 02 00 00];
			data = [01 00 00 00 00 00 00 00 20 00 00 00 12 00 00 00 80 00 00 00 05 00 00 00 03 00 00 00 00 00 00 00 08 00 00 00 10 00 00 00 18 00 00 00 1c 00 00 00 20 00 00 00 24 00 00 00 26 00 00 00 28 00 00 00 29 00 00 00 2a 00 00 00 2b 00 00 00 2c 00 00 00 2d 00 00 00 2e 00 00 00 2f 00 00 00 30 00 00 00 31 00 00 00 32 00 00 00 33 00 00 00 34 00 00 00 35 00 00 00 36 00 00 00 37 00 00 00 38 00 00 00 39 00 00 00 3a 00 00 00 3b 00 00 00 3c 00 00 00 3d 00 00 00 3e 00 00 00 3f 00 00 00 03 00 00 00 03 00 00 00 03 00 00 00 02 00 00 00 02 00 00 00 02 00 00 00 01 00 00 00 01 00 00 00 00 00 00 00 00 00 00 00 00 00 00 00 00 00 00 00 00 00 00 00 00 00 00 00 00 00 00 00 00 00 00 00 00 00 00 00 00 00 00 00 00 00 00 00 00 00 00 00 00 00 00 00 00 00 00 00 00 00 00 00 00 00 00 00 00 00 00 00 00 00 00 00 00 00 00 00 00 00 00 00 00 00 00 00 00 00 00 00 00 00 00 00 00 00 00 00 ff 0f 00 00 f7 0f 00 00 d8 0f 00 00 a1 0f 00 00 54 0f 00 00 f1 0e 00 00 7b 0e 00 00 f7 0d 00 00 68 0d 00 00 d1 0c 00 00 37 0c 00 00 9d 0b 00 00 04 0b 00 00 70 0a 00 00 e1 09 00 00 59 09 00 00 d8 08 00 00 5f 08 00 00 ee 07 00 00 84 07 00 00 22 07 00 00 c7 06 00 00 73 06 00 00 24 06 00 00 dc 05 00 00 5c 05 00 00 ee 04 00 00 90 04 00 00 3f 04 00 00 f9 03 00 00 bd 03 00 00 88 03 00 00 5b 03 00 00 32 03 00 00 0f 03 00 00 f0 02 00 00 d4 02 00 00 a6 02 00 00 80 02 00 00 62 02 00 00 49 02 00 00 23 02 00 00 08 02 00 00 f3 01 00 00 e4 01 00 00 d8 01 00 00 cf 01 00 00 c8 01 00 00 c2 01 00 00 bd 01 00 00 b9 01 00 00 b5 01 00 00 b2 01 00 00 b0 01 00 00 ae 01 00 00 ac 01 00 00 aa 01 00 00 a9 01 00 00 a7 01 00 00 a6 01 00 00 a5 01 00 00 a4 01 00 00 a4 01 00 00 a3 01 00 00 a2 01 00 00 50 00 00 00 20 00 00 00 20 00 00 00 ff 00 00 00 20 00 00 00 20 00 00 00 ff 00 00 00 00 00 00 00 00 00 00 00 00 00 00 00 00 00 00 00 00 00 00 00 00 00 00 00 00 00 00 00 00 00 00 00 00 00 00 00 00 00 00 00 00 00 00 00 00 00 00 00 00 00 00 00 00 00 00 00 00 00 00 00 00 00 00 00 00 00 00 00 00 00 00 00 00 00 00 00 00 00 00 00 00 00 00 00 00 00 00 00 00 00 00 00 00 00 00 00 00 00 00 00 00 00 00 00 00 00 00 00 00 00 00 00 00 00 00 00 00 00 00 00 00 00 00 00 00 00 00 00 00 00 00 00 00 00 00 00 00 00 00 00 00 00 00 00 00 00 00 00 00 00 00 00 00 00 00 00 00 00 00 00 00 00 00 00 00 00 00 00];
		};
		iq_defog {
			size = [84 00 00 00];
			data = [00 00 00 00 00 00 00 00 00 00 00 00 04 00 5b 02 ff 60 c0 c0 c0 c0 c0 c0 c0 c0 c0 c0 c0 c0 c0 c0 c0 c0 c0 00 28 00 00 03 0f 80 28 00 00 03 0f 80 28 00 00 03 0f 80 28 00 00 03 0f 80 28 00 00 03 05 80 28 00 00 03 00 80 28 00 00 03 00 80 28 00 00 03 00 80 28 00 00 03 00 80 28 00 00 03 00 80 28 00 00 03 00 80 28 00 00 03 00 80 28 00 00 03 00 80 28 00 00 03 00 80 28 00 00 03 00 80 28 00 00 03 ff 80];
		};
		iq_shdr {
			size = [f0 01 00 00];
			data = [00 00 00 00 00 00 00 00 10 00 00 00 01 00 00 00 00 0c 09 00 c0 00 06 00 02 00 00 00 00 0c 09 00 c0 00 06 00 00 01 00 02 04 08 0a 0c 0e 10 0e 0c 0a 08 06 04 02 00 00 00 00 00 00 00 08 00 02 04 06 08 0a 0c 0e 10 12 14 16 18 1a 1c 1e 20 22 24 26 28 2a 2c 2e 30 32 34 36 38 3a 3c 3e 01 01 01 01 01 01 01 01 01 01 01 01 01 01 01 01 01 01 01 01 01 01 01 01 01 01 01 01 01 01 01 01 00 00 00 43 03 e9 04 06 06 de 06 8b 07 1c 08 98 08 05 09 67 09 be 09 0e 0a 57 0a 9b 0a d9 0a 14 0b 4b 0b 7f 0b b0 0b de 0b 0a 0c 34 0c 5c 0c 83 0c a8 0c cb 0c ed 0c 0d 0d 2d 0d 4b 0d 69 0d 85 0d a1 0d bc 0d d6 0d ef 0d 08 0e 20 0e 37 0e 4e 0e 64 0e 79 0e 8e 0e a3 0e b7 0e cb 0e de 0e f1 0e 03 0f 15 0f 27 0f 38 0f 49 0f 5a 0f 6a 0f 7a 0f 8a 0f 9a 0f a9 0f b8 0f c7 0f d5 0f e4 0f f2 0f ff 0f 00 01 04 05 06 07 08 08 00 00 01 02 03 00 e0 00 04 05 06 07 08 08 00 00 01 02 03 00 e0 00 04 05 06 07 08 08 00 00 01 02 03 00 e0 00 04 05 06 07 08 08 00 00 01 02 03 00 e0 00 04 05 06 07 08 08 00 00 01 02 03 00 e0 00 04 05 06 07 08 08 00 00 01 02 03 00 e0 00 04 05 06 07 08 08 00 00 01 02 03 00 e0 00 04 05 06 07 08 08 00 00 01 02 03 00 e0 00 04 05 06 07 08 08 00 00 01 02 03 00 e0 00 04 05 06 07 08 08 00 00 01 02 03 00 e0 00 04 05 06 07 08 08 00 00 01 02 03 00 e0 00 04 05 06 07 08 08 00 00 01 02 03 00 e0 00 04 05 06 07 08 08 00 00 01 02 03 00 e0 00 04 05 06 07 08 08 00 00 01 02 03 00 e0 00 04 05 06 07 08 08 00 00 01 02 03 00 e0 00 04 05 06 07 08 08 00 00 01 02 03 00 e0 00 04 05 06 07 08 08 00 00 01 02 03 00 00 00];
		};
		iq_rgbir {
			size = [28 00 00 00];
			data = [00 00 00 00 cc 00 00 00 cc 00 00 00 e6 00 00 00 00 01 00 00 cc 00 00 00 cc 00 00 00 e6 00 00 00 dc 00 00 00 f0 00 00 00];
		};
		iq_companding {
			size = [18 01 00 00];
			data = [00 02 00 00 00 03 00 00 00 0a 00 00 ff 0f 00 00 ff 0f 00 00 ff 0f 00 00 ff 0f 00 00 ff 0f 00 00 ff 0f 00 00 ff 0f 00 00 ff 0f 00 00 00 00 00 00 00 01 00 00 00 02 00 00 00 08 00 00 00 08 00 00 00 08 00 00 00 08 00 00 00 08 00 00 00 08 00 00 00 08 00 00 00 08 00 00 00 08 00 00 04 00 00 00 05 00 00 00 06 00 00 00 08 00 00 00 08 00 00 00 08 00 00 00 08 00 00 00 08 00 00 00 08 00 00 00 08 00 00 00 08 00 00 00 08 00 00 00 0a 00 00 00 0b 00 00 00 0c 00 00 00 0d 00 00 00 0e 00 00 00 0f 00 00 00 10 00 00 00 10 00 00 00 10 00 00 00 10 00 00 00 10 00 00 00 00 00 00 00 00 02 00 00 00 04 00 00 00 06 00 00 00 08 00 00 00 0a 00 00 00 0c 00 00 00 0c 00 00 00 0c 00 00 00 0c 00 00 00 0c 00 00 00 0c 00 00 03 00 00 00 04 00 00 00 05 00 00 00 06 00 00 00 07 00 00 00 08 00 00 00 09 00 00 00 09 00 00 00 09 00 00 00 09 00 00 00 09 00 00 00 09 00 00 00];
		};
		iq_post_3dnr {
			size = [40 02 00 00];
			data = [01 00 00 00 00 00 00 00 01 00 00 00 06 08 0a 10 08 00 10 10 10 01 02 01 01 02 01 0a 0f 14 0a 0f 14 01 03 01 01 03 01 0a 0f 14 0a 0f 14 02 04 06 10 08 00 04 04 04 01 02 01 01 02 01 0a 0f 14 0a 0f 14 01 03 01 01 03 01 0a 0f 14 0a 0f 14 02 04 06 10 08 00 04 04 04 01 02 01 01 02 01 0f 14 19 0f 14 19 01 03 01 01 03 01 0f 14 19 0f 14 19 06 08 0a 10 08 00 05 04 04 01 02 01 01 02 01 0c 12 1e 0c 1e 1e 01 03 01 01 03 01 0a 0f 16 0a 0f 14 07 09 0b 10 08 00 06 08 08 01 02 01 01 03 01 0a 12 1c 0c 12 24 02 05 02 01 03 01 08 0f 18 08 0f 18 08 0a 0c 10 08 00 07 08 08 03 05 03 01 02 01 0c 12 1e 0c 12 1e 01 03 01 01 03 01 0c 12 1e 0c 32 1e 06 08 0a 10 08 00 08 10 10 01 03 01 01 03 01 0f 14 23 0f 14 23 01 03 01 01 03 01 0c 14 1e 0c 14 46 07 09 0b 10 08 00 09 10 10 01 03 01 01 03 01 14 1e 28 14 1e 28 01 03 01 01 03 01 0f 19 23 0f 19 50 08 09 0a 10 08 00 0a 10 10 01 03 01 01 03 01 1e 28 32 1e 28 32 01 03 01 01 03 01 14 19 23 14 19 23 09 0a 0b 10 08 00 0b 10 10 01 03 01 01 03 01 50 5a 64 50 5a 64 01 03 01 01 03 01 50 5a 64 50 5a 64 0a 0b 0c 10 08 00 0c 10 10 01 03 01 01 03 01 5a 64 6e 5a 64 6e 01 03 01 01 03 01 5a 64 6e 5a 64 6e 0b 0c 0d 10 08 00 0d 10 10 01 03 01 01 03 01 64 78 8c 64 78 8c 01 03 01 01 03 01 64 78 8c 64 78 8c 0c 0d 0e 10 08 00 0d 10 10 01 03 01 01 03 01 64 78 8c 64 78 8c 01 03 01 01 03 01 64 78 8c 64 78 8c 0d 0e 0f 10 08 00 0d 10 10 01 03 01 01 03 01 64 78 8c 64 78 8c 01 03 01 01 03 01 64 78 8c 64 78 8c 0e 0f 10 10 08 00 0d 10 10 01 03 01 01 03 01 64 78 8c 64 78 8c 01 03 01 01 03 01 64 78 8c 64 78 8c 0f 10 11 10 08 00 0d 10 10 01 03 01 01 03 01 64 78 8c 64 78 8c 01 03 01 01 03 01 64 78 8c 64 78 8c 0f 10 11 10 08 00 0d 10 10 01 03 01 01 03 01 64 78 8c 64 78 8c 01 03 01 01 03 01 64 78 8c 64 78 8c 00 00 00];
		};
		iq_rgbir_enh {
			size = [18 01 00 00];
			data = [01 00 00 00 00 00 00 00 32 00 00 00 10 00 00 00 10 00 00 00 10 00 00 00 10 00 00 00 10 00 00 00 10 00 00 00 10 00 00 00 10 00 00 00 10 00 00 00 10 00 00 00 10 00 00 00 10 00 00 00 10 00 00 00 10 00 00 00 10 00 00 00 10 00 00 00 50 00 00 00 20 00 00 00 20 00 00 00 20 00 00 00 20 00 00 00 20 00 00 00 20 00 00 00 20 00 00 00 20 00 00 00 20 00 00 00 20 00 00 00 20 00 00 00 20 00 00 00 20 00 00 00 20 00 00 00 20 00 00 00 20 00 00 00 98 00 00 00 50 00 00 00 50 00 00 00 50 00 00 00 50 00 00 00 50 00 00 00 50 00 00 00 50 00 00 00 50 00 00 00 50 00 00 00 50 00 00 00 50 00 00 00 50 00 00 00 50 00 00 00 50 00 00 00 50 00 00 00 50 00 00 00 ff 00 00 00 a0 00 00 00 a0 00 00 00 a0 00 00 00 a0 00 00 00 a0 00 00 00 a0 00 00 00 a0 00 00 00 a0 00 00 00 a0 00 00 00 a0 00 00 00 a0 00 00 00 a0 00 00 00 a0 00 00 00 a0 00 00 00 a0 00 00 00 a0 00 00 00];
		};
	};
};
